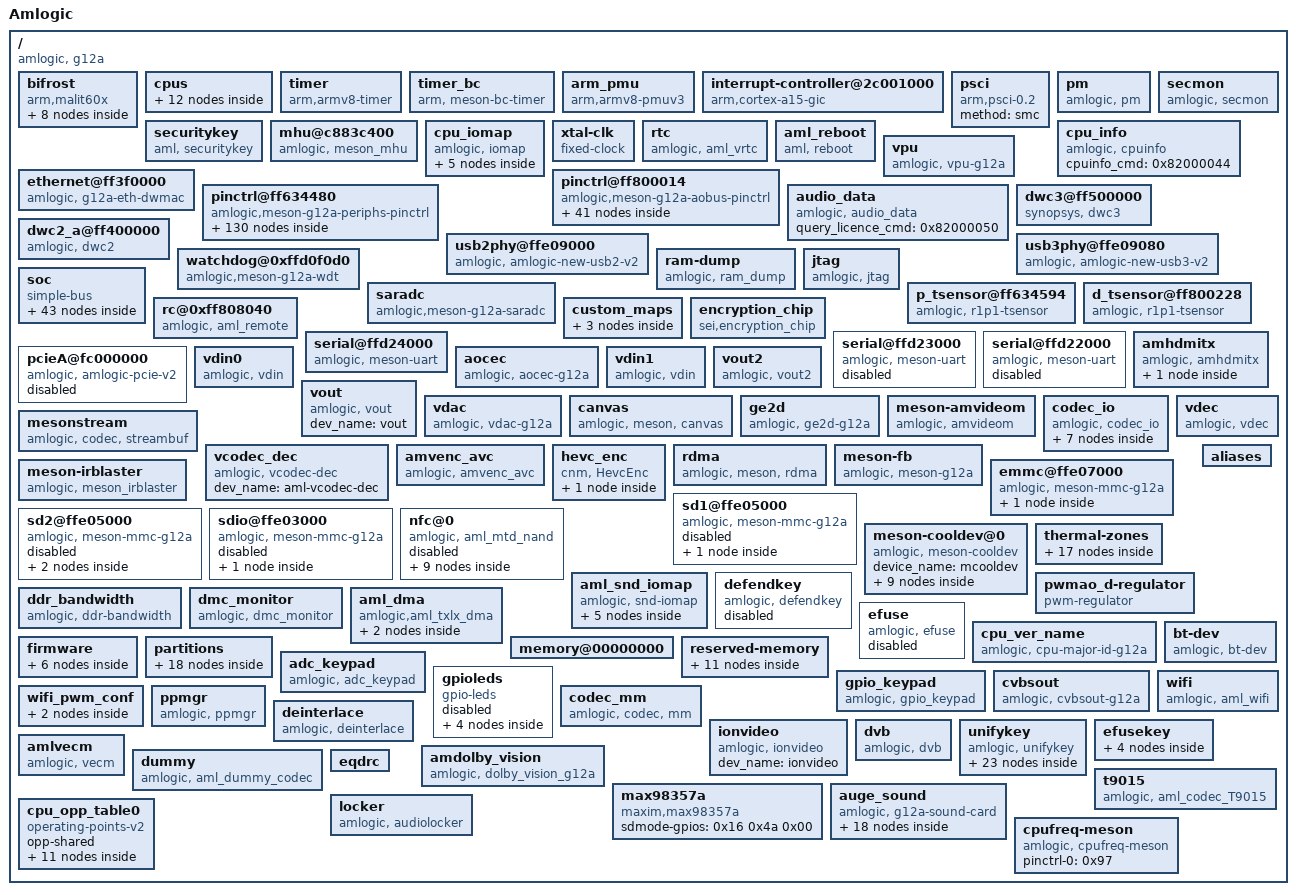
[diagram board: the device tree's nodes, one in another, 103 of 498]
/dts-v1/;

/ {
	model = "Amlogic";
	amlogic-dt-id = "g12a_SEI501";
	compatible = "amlogic, g12a";
	interrupt-parent = <0x01>;
	#address-cells = <0x02>;
	#size-cells = <0x02>;

	bifrost {
		compatible = "arm,malit60x\0arm,malit6xx\0arm,mali-midgard";
		#cooling-cells = <0x02>;
		reg = <0x00 0xffe40000 0x00 0x4000 0x00 0xffd01000 0x00 0x1000 0x00 0xff800000 0x00 0x1000 0x00 0xff63c000 0x00 0x1000 0x00 0xffd01000 0x00 0x1000>;
		interrupt-parent = <0x01>;
		interrupts = <0x00 0xa0 0x04 0x00 0xa1 0x04 0x00 0xa2 0x04>;
		interrupt-names = "GPU\0MMU\0JOB";
		num_of_pp = <0x02>;
		sc_mpp = <0x01>;
		clocks = <0x02 0x83 0x02 0x07>;
		clock-names = "gpu_mux\0gp0_pll";
		tbl = <0x03 0x04 0x05 0x06 0x07 0x07>;
		linux,phandle = <0x98>;
		phandle = <0x98>;

		clk125_cfg {
			clk_freq = <0x7735940>;
			clk_parent = "fclk_div4";
			clkp_freq = <0x1dcd6500>;
			clk_reg = <0xa03>;
			voltage = <0x47e>;
			keep_count = <0x05>;
			threshold = <0x1e 0x78>;
			linux,phandle = <0x99>;
			phandle = <0x99>;
		};

		dvfs250_cfg {
			clk_freq = <0xee6b280>;
			clk_parent = "fclk_div4";
			clkp_freq = <0x1dcd6500>;
			clk_reg = <0xa01>;
			voltage = <0x47e>;
			keep_count = <0x05>;
			threshold = <0x50 0xaa>;
			linux,phandle = <0x9a>;
			phandle = <0x9a>;
		};

		dvfs285_cfg {
			clk_freq = <0x1107a76d>;
			clk_parent = "fclk_div7";
			clkp_freq = <0x1107a76d>;
			clk_reg = <0xe00>;
			voltage = <0x47e>;
			keep_count = <0x05>;
			threshold = <0x64 0xbe>;
			linux,phandle = <0x03>;
			phandle = <0x03>;
		};

		dvfs400_cfg {
			clk_freq = <0x17d78400>;
			clk_parent = "fclk_div5";
			clkp_freq = <0x17d78400>;
			clk_reg = <0xc00>;
			voltage = <0x47e>;
			keep_count = <0x05>;
			threshold = <0x98 0xcf>;
			linux,phandle = <0x04>;
			phandle = <0x04>;
		};

		dvfs500_cfg {
			clk_freq = <0x1dcd6500>;
			clk_parent = "fclk_div4";
			clkp_freq = <0x1dcd6500>;
			clk_reg = <0xa00>;
			voltage = <0x47e>;
			keep_count = <0x05>;
			threshold = <0xb4 0xdc>;
			linux,phandle = <0x05>;
			phandle = <0x05>;
		};

		dvfs666_cfg {
			clk_freq = <0x27bc86aa>;
			clk_parent = "fclk_div3";
			clkp_freq = <0x27bc86aa>;
			clk_reg = <0x800>;
			voltage = <0x47e>;
			keep_count = <0x05>;
			threshold = <0xd2 0xec>;
			linux,phandle = <0x06>;
			phandle = <0x06>;
		};

		dvfs800_cfg {
			clk_freq = <0x2faf0800>;
			clk_parent = "fclk_div2p5";
			clkp_freq = <0x2faf0800>;
			clk_reg = <0x600>;
			voltage = <0x47e>;
			keep_count = <0x05>;
			threshold = <0xe6 0xff>;
			linux,phandle = <0x9b>;
			phandle = <0x9b>;
		};

		dvfs850_cfg {
			clk_freq = <0x326cef80>;
			clk_parent = "gp0_pll";
			clkp_freq = <0x326cef80>;
			clk_reg = <0x200>;
			voltage = <0x47e>;
			keep_count = <0x05>;
			threshold = <0xe6 0xff>;
			linux,phandle = <0x07>;
			phandle = <0x07>;
		};
	};

	cpus {
		#address-cells = <0x02>;
		#size-cells = <0x00>;
		linux,phandle = <0x9c>;
		phandle = <0x9c>;

		cpu-map {

			cluster0 {
				linux,phandle = <0x9d>;
				phandle = <0x9d>;

				core0 {
					cpu = <0x08>;
				};

				core1 {
					cpu = <0x09>;
				};

				core2 {
					cpu = <0x0a>;
				};

				core3 {
					cpu = <0x0b>;
				};
			};
		};

		cpu@0 {
			device_type = "cpu";
			compatible = "arm,cortex-a53\0arm,armv8";
			reg = <0x00 0x00>;
			enable-method = "psci";
			cpu-idle-states = <0x0c>;
			clocks = <0x02 0x17 0x02 0x16 0x02 0x00>;
			clock-names = "core_clk\0low_freq_clk_parent\0high_freq_clk_parent";
			operating-points-v2 = <0x0d>;
			cpu-supply = <0x0e>;
			voltage-tolerance = <0x00>;
			clock-latency = <0xc350>;
			linux,phandle = <0x08>;
			phandle = <0x08>;
		};

		cpu@1 {
			device_type = "cpu";
			compatible = "arm,cortex-a53\0arm,armv8";
			reg = <0x00 0x01>;
			enable-method = "psci";
			cpu-idle-states = <0x0c>;
			clocks = <0x02 0x17 0x02 0x16 0x02 0x00>;
			clock-names = "core_clk\0low_freq_clk_parent\0high_freq_clk_parent";
			operating-points-v2 = <0x0d>;
			cpu-supply = <0x0e>;
			voltage-tolerance = <0x00>;
			clock-latency = <0xc350>;
			linux,phandle = <0x09>;
			phandle = <0x09>;
		};

		cpu@2 {
			device_type = "cpu";
			compatible = "arm,cortex-a53\0arm,armv8";
			reg = <0x00 0x02>;
			enable-method = "psci";
			cpu-idle-states = <0x0c>;
			clocks = <0x02 0x17 0x02 0x16 0x02 0x00>;
			clock-names = "core_clk\0low_freq_clk_parent\0high_freq_clk_parent";
			operating-points-v2 = <0x0d>;
			cpu-supply = <0x0e>;
			voltage-tolerance = <0x00>;
			clock-latency = <0xc350>;
			linux,phandle = <0x0a>;
			phandle = <0x0a>;
		};

		cpu@3 {
			device_type = "cpu";
			compatible = "arm,cortex-a53\0arm,armv8";
			reg = <0x00 0x03>;
			enable-method = "psci";
			cpu-idle-states = <0x0c>;
			clocks = <0x02 0x17 0x02 0x16 0x02 0x00>;
			clock-names = "core_clk\0low_freq_clk_parent\0high_freq_clk_parent";
			operating-points-v2 = <0x0d>;
			cpu-supply = <0x0e>;
			voltage-tolerance = <0x00>;
			clock-latency = <0xc350>;
			linux,phandle = <0x0b>;
			phandle = <0x0b>;
		};

		idle-states {
			entry-method = "arm,psci-0.2";

			cpu-sleep-0 {
				compatible = "arm,idle-state";
				arm,psci-suspend-param = <0x10000>;
				local-timer-stop;
				entry-latency-us = <0x1388>;
				exit-latency-us = <0x1388>;
				min-residency-us = <0x3a98>;
				linux,phandle = <0x0c>;
				phandle = <0x0c>;
			};
		};
	};

	timer {
		compatible = "arm,armv8-timer";
		interrupts = <0x01 0x0d 0xff08 0x01 0x0e 0xff08 0x01 0x0b 0xff08 0x01 0x0a 0xff08>;
	};

	timer_bc {
		compatible = "arm, meson-bc-timer";
		reg = <0x00 0xffd0f190 0x00 0x04 0x00 0xffd0f194 0x00 0x04>;
		timer_name = "Meson TimerF";
		clockevent-rating = <0x12c>;
		clockevent-shift = <0x14>;
		clockevent-features = <0x23>;
		interrupts = <0x00 0x3c 0x01>;
		bit_enable = <0x10>;
		bit_mode = <0x0c>;
		bit_resolution = <0x00>;
	};

	arm_pmu {
		compatible = "arm,armv8-pmuv3";
		interrupts = <0x00 0x89 0x04>;
		reg = <0x00 0xff634400 0x00 0x1000>;
		sys_cpu_status0_offset = <0xa0>;
		sys_cpu_status0_pmuirq_mask = <0x0f>;
		relax_timer_ns = <0x989680>;
		max_wait_cnt = <0x2710>;
	};

	interrupt-controller@2c001000 {
		compatible = "arm,cortex-a15-gic\0arm,cortex-a9-gic";
		#interrupt-cells = <0x03>;
		#address-cells = <0x00>;
		interrupt-controller;
		reg = <0x00 0xffc01000 0x00 0x1000 0x00 0xffc02000 0x00 0x100>;
		interrupts = <0x01 0x09 0xf04>;
		linux,phandle = <0x01>;
		phandle = <0x01>;
	};

	psci {
		compatible = "arm,psci-0.2";
		method = "smc";
	};

	pm {
		compatible = "amlogic, pm";
		status = "okay";
		device_name = "aml_pm";
		reg = <0x00 0xff8000a8 0x00 0x04 0x00 0xff80023c 0x00 0x04>;
		linux,phandle = <0x9e>;
		phandle = <0x9e>;
	};

	secmon {
		compatible = "amlogic, secmon";
		memory-region = <0x0f>;
		in_base_func = <0x82000020>;
		out_base_func = <0x82000021>;
		reserve_mem_size = <0x300000>;
	};

	securitykey {
		compatible = "aml, securitykey";
		storage_query = <0x82000060>;
		storage_read = <0x82000061>;
		storage_write = <0x82000062>;
		storage_tell = <0x82000063>;
		storage_verify = <0x82000064>;
		storage_status = <0x82000065>;
		storage_list = <0x82000067>;
		storage_remove = <0x82000068>;
		storage_in_func = <0x82000023>;
		storage_out_func = <0x82000024>;
		storage_block_func = <0x82000025>;
		storage_size_func = <0x82000027>;
		storage_set_enctype = <0x8200006a>;
		storage_get_enctype = <0x8200006b>;
		storage_version = <0x8200006c>;
	};

	mhu@c883c400 {
		compatible = "amlogic, meson_mhu";
		reg = <0x00 0xff63c400 0x00 0x4c 0x00 0xfffe7000 0x00 0x800>;
		interrupts = <0x00 0xd1 0x01 0x00 0xd2 0x01>;
		#mbox-cells = <0x01>;
		mbox-names = "cpu_to_scp_low\0cpu_to_scp_high";
		mboxes = <0x10 0x00 0x10 0x01>;
		linux,phandle = <0x10>;
		phandle = <0x10>;
	};

	cpu_iomap {
		compatible = "amlogic, iomap";
		#address-cells = <0x02>;
		#size-cells = <0x02>;
		ranges;

		io_cbus_base {
			reg = <0x00 0xffd00000 0x00 0x26000>;
		};

		io_apb_base {
			reg = <0x00 0xffe01000 0x00 0x7f000>;
		};

		io_aobus_base {
			reg = <0x00 0xff800000 0x00 0xb000>;
		};

		io_vapb_base {
			reg = <0x00 0xff900000 0x00 0x50000>;
		};

		io_hiu_base {
			reg = <0x00 0xff63c000 0x00 0x2000>;
		};
	};

	xtal-clk {
		compatible = "fixed-clock";
		clock-frequency = <0x16e3600>;
		clock-output-names = "xtal";
		#clock-cells = <0x00>;
		linux,phandle = <0x14>;
		phandle = <0x14>;
	};

	rtc {
		compatible = "amlogic, aml_vrtc";
		alarm_reg_addr = <0xff8000a8>;
		timer_e_addr = <0xffd0f188>;
		init_date = "2015/01/01";
		status = "okay";
	};

	cpu_info {
		compatible = "amlogic, cpuinfo";
		status = "okay";
		cpuinfo_cmd = <0x82000044>;
	};

	aml_reboot {
		compatible = "aml, reboot";
		sys_reset = <0x84000009>;
		sys_poweroff = <0x84000008>;
	};

	vpu {
		compatible = "amlogic, vpu-g12a";
		dev_name = "vpu";
		status = "okay";
		clocks = <0x02 0x95 0x02 0x4c 0x02 0x87 0x02 0x8b 0x02 0x8c>;
		clock-names = "vapb_clk\0vpu_intr_gate\0vpu_clk0\0vpu_clk1\0vpu_clk";
		clk_level = <0x07>;
	};

	ethernet@ff3f0000 {
		compatible = "amlogic, g12a-eth-dwmac\0snps,dwmac";
		reg = <0x00 0xff3f0000 0x00 0x10000 0x00 0xff634540 0x00 0x08 0x00 0xff64c000 0x00 0xa0>;
		reg-names = "eth_base\0eth_cfg\0eth_pll";
		interrupts = <0x00 0x08 0x01>;
		interrupt-names = "macirq";
		status = "okay";
		clocks = <0x02 0x38>;
		clock-names = "ethclk81";
		pll_val = <0x9c0040a 0x927e0000 0xac5f49e5>;
		analog_val = <0x20200000 0xc000 0x23>;
		pinctrl-names = "internal_eth_pins";
		pinctrl-0 = <0x11>;
		mc_val = <0x4be04>;
		internal_phy = <0x01>;
		linux,phandle = <0x9f>;
		phandle = <0x9f>;
	};

	pinctrl@ff800014 {
		compatible = "amlogic,meson-g12a-aobus-pinctrl";
		#address-cells = <0x02>;
		#size-cells = <0x02>;
		ranges;
		linux,phandle = <0xa0>;
		phandle = <0xa0>;

		ao-bank@ff800014 {
			reg = <0x00 0xff800014 0x00 0x08 0x00 0xff800024 0x00 0x14 0x00 0xff80001c 0x00 0x08>;
			reg-names = "mux\0gpio\0drive-strength";
			gpio-controller;
			#gpio-cells = <0x02>;
			linux,phandle = <0x15>;
			phandle = <0x15>;
		};

		sd_to_ao_uart_clr_pins {
			linux,phandle = <0x3e>;
			phandle = <0x3e>;

			mux {
				groups = "GPIOAO_0\0GPIOAO_1";
				function = "gpio_aobus";
			};
		};

		sd_to_ao_uart_pins {
			linux,phandle = <0x40>;
			phandle = <0x40>;

			mux {
				groups = "uart_ao_tx_a\0uart_ao_rx_a";
				function = "uart_ao_a";
				bias-pull-up;
				input-enable;
			};
		};

		ao_uart {
			linux,phandle = <0xa1>;
			phandle = <0xa1>;

			mux {
				groups = "uart_ao_tx_a\0uart_ao_rx_a";
				function = "uart_ao_a";
			};
		};

		ao_b_uart {
			linux,phandle = <0x1a>;
			phandle = <0x1a>;

			mux {
				groups = "uart_ao_tx_b_2\0uart_ao_rx_b_3";
				function = "uart_ao_b";
			};
		};

		ao_i2c_pins1 {
			linux,phandle = <0xa2>;
			phandle = <0xa2>;

			mux {
				groups = "i2c_ao_sck\0i2c_ao_sda";
				function = "i2c_ao";
				drive-strength = <0x02>;
			};
		};

		ao_i2c_pins2 {
			linux,phandle = <0xa3>;
			phandle = <0xa3>;

			mux {
				groups = "i2c_ao_sck_e\0i2c_ao_sda_e";
				function = "i2c_ao";
				drive-strength = <0x02>;
			};
		};

		ao_i2c_slave_pins {
			linux,phandle = <0x19>;
			phandle = <0x19>;

			mux {
				groups = "i2c_ao_slave_sck\0i2c_ao_slave_sda";
				function = "i2c_ao_slave";
			};
		};

		pwm_ao_a {
			linux,phandle = <0xa4>;
			phandle = <0xa4>;

			mux {
				groups = "pwm_ao_a";
				function = "pwm_ao_a";
			};
		};

		pwm_ao_a_hiz {
			linux,phandle = <0xa5>;
			phandle = <0xa5>;

			mux {
				groups = "pwm_ao_a_hiz";
				function = "pwm_ao_a";
			};
		};

		pwm_ao_b {
			linux,phandle = <0xa6>;
			phandle = <0xa6>;

			mux {
				groups = "pwm_ao_b";
				function = "pwm_ao_b";
			};
		};

		pwm_ao_c_pins1 {
			linux,phandle = <0xa7>;
			phandle = <0xa7>;

			mux {
				groups = "pwm_ao_c_4";
				function = "pwm_ao_c";
			};
		};

		pwm_ao_c_pins2 {
			linux,phandle = <0xa8>;
			phandle = <0xa8>;

			mux {
				groups = "pwm_ao_c_6";
				function = "pwm_ao_c";
			};
		};

		pwm_ao_c_hiz {
			linux,phandle = <0xa9>;
			phandle = <0xa9>;

			mux {
				groups = "pwm_ao_c_hiz_4";
				function = "pwm_ao_c";
			};
		};

		pwm_ao_d_pins1 {
			linux,phandle = <0xaa>;
			phandle = <0xaa>;

			mux {
				groups = "pwm_ao_d_5";
				function = "pwm_ao_d";
			};
		};

		pwm_ao_d_pins2 {
			linux,phandle = <0xab>;
			phandle = <0xab>;

			mux {
				groups = "pwm_ao_d_10";
				function = "pwm_ao_d";
			};
		};

		pwm_ao_d_pins3 {
			linux,phandle = <0x97>;
			phandle = <0x97>;

			mux {
				groups = "pwm_ao_d_e";
				function = "pwm_ao_d";
			};
		};

		ao_ceca {
			linux,phandle = <0xac>;
			phandle = <0xac>;

			mux {
				groups = "cec_ao_a";
				function = "cec_ao";
			};
		};

		ao_cecb {
			linux,phandle = <0xad>;
			phandle = <0xad>;

			mux {
				groups = "cec_ao_b";
				function = "cec_ao";
			};
		};

		remote_pin {
			linux,phandle = <0x25>;
			phandle = <0x25>;

			mux {
				groups = "remote_input_ao";
				function = "remote_input_ao";
			};
		};

		irblaster_pin {
			linux,phandle = <0x37>;
			phandle = <0x37>;

			mux {
				groups = "remote_out_ao";
				function = "remote_out_ao";
			};
		};
	};

	pinctrl@ff634480 {
		compatible = "amlogic,meson-g12a-periphs-pinctrl";
		#address-cells = <0x02>;
		#size-cells = <0x02>;
		ranges;
		linux,phandle = <0xae>;
		phandle = <0xae>;

		banks@ff6346c0 {
			reg = <0x00 0xff6346c0 0x00 0x40 0x00 0xff6344e8 0x00 0x18 0x00 0xff634520 0x00 0x18 0x00 0xff634440 0x00 0x4c 0x00 0xff634740 0x00 0x1c>;
			reg-names = "mux\0pull\0pull-enable\0gpio\0drive-strength";
			gpio-controller;
			#gpio-cells = <0x02>;
			linux,phandle = <0x16>;
			phandle = <0x16>;
		};

		emmc_clk_cmd_pins {
			linux,phandle = <0x38>;
			phandle = <0x38>;

			mux {
				groups = "emmc_clk\0emmc_cmd";
				function = "emmc";
				input-enable;
				bias-pull-up;
			};
		};

		emmc_conf_pull_up {
			linux,phandle = <0x39>;
			phandle = <0x39>;

			mux {
				groups = "emmc_nand_d7\0emmc_nand_d6\0emmc_nand_d5\0emmc_nand_d4\0emmc_nand_d3\0emmc_nand_d2\0emmc_nand_d1\0emmc_nand_d0\0emmc_clk\0emmc_cmd";
				function = "emmc";
				input-enable;
				bias-pull-up;
			};
		};

		emmc_conf_pull_done {
			linux,phandle = <0x3a>;
			phandle = <0x3a>;

			mux {
				groups = "emmc_nand_ds";
				function = "emmc";
				input-enable;
				bias-pull-down;
			};
		};

		sd_clk_cmd_pins {
			linux,phandle = <0x3c>;
			phandle = <0x3c>;

			mux {
				groups = "sdcard_cmd_c";
				function = "sdcard";
				input-enable;
				bias-pull-up;
				drive-strength = <0x03>;
			};

			mux1 {
				groups = "sdcard_clk_c";
				function = "sdcard";
				bias-pull-up;
				output-high;
				drive-strength = <0x03>;
			};
		};

		sd_all_pins {
			linux,phandle = <0x3b>;
			phandle = <0x3b>;

			mux {
				groups = "sdcard_d0_c\0sdcard_d1_c\0sdcard_d2_c\0sdcard_d3_c\0sdcard_cmd_c";
				function = "sdcard";
				input-enable;
				bias-pull-up;
				drive-strength = <0x03>;
			};

			mux1 {
				groups = "sdcard_clk_c";
				function = "sdcard";
				bias-pull-up;
				output-high;
				drive-strength = <0x03>;
			};
		};

		sd_1bit_pins {
			linux,phandle = <0x3d>;
			phandle = <0x3d>;

			mux {
				groups = "sdcard_d0_c\0sdcard_cmd_c";
				function = "sdcard";
				input-enable;
				bias-pull-up;
				drive-strength = <0x03>;
			};

			mux1 {
				groups = "sdcard_clk_c";
				function = "sdcard";
				bias-pull-up;
				output-high;
				drive-strength = <0x03>;
			};
		};

		sd_clr_all_pins {
			linux,phandle = <0x44>;
			phandle = <0x44>;

			mux {
				groups = "GPIOC_0\0GPIOC_1\0GPIOC_2\0GPIOC_3\0GPIOC_5";
				function = "gpio_periphs";
				output-high;
			};

			mux1 {
				groups = "GPIOC_4";
				function = "gpio_periphs";
				output-low;
			};
		};

		sd_clr_noall_pins {
			linux,phandle = <0x43>;
			phandle = <0x43>;

			mux {
				groups = "GPIOC_0\0GPIOC_1\0GPIOC_4\0GPIOC_5";
				function = "gpio_periphs";
				output-high;
			};
		};

		ao_to_sd_uart_pins {
			linux,phandle = <0x3f>;
			phandle = <0x3f>;

			mux {
				groups = "uart_ao_tx_a_c3\0uart_ao_rx_a_c2";
				function = "uart_ao_a_ee";
				bias-pull-up;
				input-enable;
			};
		};

		sdio_clk_cmd_pins {
			linux,phandle = <0x48>;
			phandle = <0x48>;

			mux {
				groups = "sdio_clk\0sdio_cmd";
				function = "sdio";
				input-enable;
				bias-pull-up;
				drive-strength = <0x03>;
			};
		};

		sdio_all_pins {
			linux,phandle = <0x47>;
			phandle = <0x47>;

			mux {
				groups = "sdio_d0\0sdio_d1\0sdio_d2\0sdio_d3\0sdio_clk\0sdio_cmd";
				function = "sdio";
				input-enable;
				bias-pull-up;
				drive-strength = <0x03>;
			};
		};

		sdio_x_clk_cmd_pins {
			linux,phandle = <0x46>;
			phandle = <0x46>;

			mux {
				groups = "GPIOX_5";
				function = "gpio_periphs";
				input-enable;
				bias-pull-up;
				drive-strength = <0x03>;
			};

			mux1 {
				groups = "GPIOX_4";
				function = "gpio_periphs";
				bias-pull-up;
				output-high;
				drive-strength = <0x03>;
			};
		};

		sdio_x_all_pins {
			linux,phandle = <0x45>;
			phandle = <0x45>;

			mux {
				groups = "GPIOX_0\0GPIOX_1\0GPIOX_2\0GPIOX_3\0GPIOX_5";
				function = "gpio_periphs";
				input-enable;
				bias-pull-up;
				drive-strength = <0x03>;
			};

			mux1 {
				groups = "GPIOX_4";
				function = "gpio_periphs";
				bias-pull-up;
				output-high;
				drive-strength = <0x03>;
			};
		};

		sdio_x_en_pins {
			linux,phandle = <0x42>;
			phandle = <0x42>;

			mux {
				groups = "sdio_dummy";
				function = "sdio";
				bias-pull-up;
				output-high;
			};
		};

		sdio_x_clr_pins {
			linux,phandle = <0x41>;
			phandle = <0x41>;

			mux {
				groups = "GPIOV_0";
				function = "gpio_periphs";
				bias-pull-up;
				output-low;
			};

			mux1 {
				groups = "GPIOX_4";
				function = "gpio_periphs";
				output-low;
			};
		};

		all_nand_pins {
			linux,phandle = <0x49>;
			phandle = <0x49>;

			mux {
				groups = "emmc_nand_d0\0emmc_nand_d1\0emmc_nand_d2\0emmc_nand_d3\0emmc_nand_d4\0emmc_nand_d5\0emmc_nand_d6\0emmc_nand_d7\0nand_ce0\0nand_ale\0nand_cle\0nand_wen_clk\0nand_ren_wr\0nand_rb0";
				function = "nand";
				input-enable;
			};
		};

		nand_cs {
			linux,phandle = <0x4a>;
			phandle = <0x4a>;

			mux {
				groups = "nand_ce0";
				function = "nand";
			};
		};

		i2c0_pins1 {
			linux,phandle = <0xaf>;
			phandle = <0xaf>;

			mux {
				groups = "i2c0_sda_c\0i2c0_sck_c";
				function = "i2c0";
				drive-strength = <0x02>;
			};
		};

		i2c0_pins2 {
			linux,phandle = <0x17>;
			phandle = <0x17>;

			mux {
				groups = "i2c0_sda_z0\0i2c0_sck_z1";
				function = "i2c0";
				drive-strength = <0x02>;
			};
		};

		i2c0_pins3 {
			linux,phandle = <0xb0>;
			phandle = <0xb0>;

			mux {
				groups = "i2c0_sda_z7\0i2c0_sck_z8";
				function = "i2c0";
				drive-strength = <0x02>;
			};
		};

		i2c1_pins1 {
			linux,phandle = <0xb1>;
			phandle = <0xb1>;

			mux {
				groups = "i2c1_sda_x\0i2c1_sck_x";
				function = "i2c1";
				drive-strength = <0x02>;
			};
		};

		i2c1_pins2 {
			linux,phandle = <0xb2>;
			phandle = <0xb2>;

			mux {
				groups = "i2c1_sda_h2\0i2c1_sck_h3";
				function = "i2c1";
				drive-strength = <0x02>;
			};
		};

		i2c1_pins3 {
			linux,phandle = <0xb3>;
			phandle = <0xb3>;

			mux {
				groups = "i2c1_sda_h6\0i2c1_sck_h7";
				function = "i2c1";
				drive-strength = <0x02>;
			};
		};

		i2c2_pins1 {
			linux,phandle = <0xb4>;
			phandle = <0xb4>;

			mux {
				groups = "i2c2_sda_x\0i2c2_sck_x";
				function = "i2c2";
				drive-strength = <0x02>;
			};
		};

		i2c2_pins2 {
			linux,phandle = <0xb5>;
			phandle = <0xb5>;

			mux {
				groups = "i2c2_sda_z\0i2c2_sck_z";
				function = "i2c2";
				drive-strength = <0x02>;
			};
		};

		i2c3_pins1 {
			linux,phandle = <0x31>;
			phandle = <0x31>;

			mux {
				groups = "i2c3_sda_h\0i2c3_sck_h";
				function = "i2c3";
				drive-strength = <0x02>;
			};
		};

		i2c3_pins2 {
			linux,phandle = <0x18>;
			phandle = <0x18>;

			mux {
				groups = "i2c3_sda_a\0i2c3_sck_a";
				function = "i2c3";
				drive-strength = <0x02>;
			};
		};

		pwm_a {
			linux,phandle = <0xb6>;
			phandle = <0xb6>;

			mux {
				groups = "pwm_a";
				function = "pwm_a";
			};
		};

		pwm_b_pins1 {
			linux,phandle = <0xb7>;
			phandle = <0xb7>;

			mux {
				groups = "pwm_b_x7";
				function = "pwm_b";
			};
		};

		pwm_b_pins2 {
			linux,phandle = <0xb8>;
			phandle = <0xb8>;

			mux {
				groups = "pwm_b_x19";
				function = "pwm_b";
			};
		};

		pwm_c_pins1 {
			linux,phandle = <0xb9>;
			phandle = <0xb9>;

			mux {
				groups = "pwm_c_c4";
				function = "pwm_c";
			};
		};

		pwm_c_pins2 {
			linux,phandle = <0xba>;
			phandle = <0xba>;

			mux {
				groups = "pwm_c_x5";
				function = "pwm_c";
			};
		};

		pwm_c_pins3 {
			linux,phandle = <0xbb>;
			phandle = <0xbb>;

			mux {
				groups = "pwm_c_x8";
				function = "pwm_c";
			};
		};

		pwm_d_pins1 {
			linux,phandle = <0xbc>;
			phandle = <0xbc>;

			mux {
				groups = "pwm_d_x3";
				function = "pwm_d";
			};
		};

		pwm_d_pins2 {
			linux,phandle = <0xbd>;
			phandle = <0xbd>;

			mux {
				groups = "pwm_d_x6";
				function = "pwm_d";
			};
		};

		pwm_e {
			linux,phandle = <0x6a>;
			phandle = <0x6a>;

			mux {
				groups = "pwm_e";
				function = "pwm_e";
			};
		};

		pwm_f_pins1 {
			linux,phandle = <0xbe>;
			phandle = <0xbe>;

			mux {
				groups = "pwm_f_x";
				function = "pwm_f";
			};
		};

		pwm_f_pins2 {
			linux,phandle = <0xbf>;
			phandle = <0xbf>;

			mux {
				groups = "pwm_f_h";
				function = "pwm_f";
			};
		};

		spicc0_pins_x {
			linux,phandle = <0xc0>;
			phandle = <0xc0>;

			mux {
				groups = "spi0_mosi_x\0spi0_miso_x\0spi0_clk_x";
				function = "spi0";
				drive-strength = <0x01>;
			};
		};

		spicc0_pins_c {
			linux,phandle = <0xc1>;
			phandle = <0xc1>;

			mux {
				groups = "spi0_mosi_c\0spi0_miso_c\0spi0_ss0_c\0spi0_clk_c";
				function = "spi0";
				drive-strength = <0x01>;
			};
		};

		spicc1_pins {
			linux,phandle = <0xc2>;
			phandle = <0xc2>;

			mux {
				groups = "spi1_mosi\0spi1_miso\0spi1_clk";
				function = "spi1";
				drive-strength = <0x01>;
			};
		};

		a_uart {
			linux,phandle = <0x2a>;
			phandle = <0x2a>;

			mux {
				groups = "uart_tx_a\0uart_rx_a\0uart_cts_a\0uart_rts_a";
				function = "uart_a";
			};
		};

		b_uart {
			linux,phandle = <0x2b>;
			phandle = <0x2b>;

			mux {
				groups = "uart_tx_b\0uart_rx_b";
				function = "uart_b";
			};
		};

		c_uart {
			linux,phandle = <0x2c>;
			phandle = <0x2c>;

			mux {
				groups = "uart_tx_c\0uart_rx_c";
				function = "uart_c";
			};
		};

		hdmitx_hpd {
			linux,phandle = <0x2e>;
			phandle = <0x2e>;

			mux {
				groups = "hdmitx_hpd_in";
				function = "hdmitx";
				bias-disable;
			};
		};

		hdmitx_hpd_gpio {
			linux,phandle = <0x30>;
			phandle = <0x30>;

			mux {
				groups = "GPIOH_1";
				function = "gpio_periphs";
				bias-disable;
			};
		};

		hdmitx_ddc {
			linux,phandle = <0x2f>;
			phandle = <0x2f>;

			mux {
				groups = "hdmitx_sda\0hdmitx_sck";
				function = "hdmitx";
				bias-disable;
				drive-strength = <0x03>;
			};
		};

		ee_ceca {
			linux,phandle = <0x32>;
			phandle = <0x32>;

			mux {
				groups = "cec_ao_a_ee";
				function = "cec_ao_ee";
			};
		};

		ee_cecb {
			linux,phandle = <0x33>;
			phandle = <0x33>;

			mux {
				groups = "cec_ao_b_ee";
				function = "cec_ao_ee";
			};
		};

		internal_eth_pins {
			linux,phandle = <0x11>;
			phandle = <0x11>;

			mux {
				groups = "eth_link_led\0eth_act_led";
				function = "eth";
			};
		};

		internal_gpio_pins {
			linux,phandle = <0xc3>;
			phandle = <0xc3>;

			mux {
				groups = "GPIOZ_14\0GPIOZ_15";
				function = "gpio_periphs";
				bias-disable;
				input-enable;
			};
		};

		external_eth_pins {
			linux,phandle = <0xc4>;
			phandle = <0xc4>;

			mux {
				groups = "eth_mdio\0eth_mdc\0eth_rgmii_rx_clk\0eth_rx_dv\0eth_rxd0\0eth_rxd1\0eth_rxd2_rgmii\0eth_rxd3_rgmii\0eth_rgmii_tx_clk\0eth_txen\0eth_txd0\0eth_txd1\0eth_txd2_rgmii\0eth_txd3_rgmii";
				function = "eth";
				drive-strength = <0x03>;
			};
		};

		tdmout_a {
			linux,phandle = <0x1d>;
			phandle = <0x1d>;

			mux {
				groups = "tdma_sclk\0tdma_fs\0tdma_dout0";
				function = "tdma_out";
			};
		};

		tdmb_mclk {
			linux,phandle = <0x1e>;
			phandle = <0x1e>;

			mux {
				groups = "mclk0_a";
				function = "mclk0";
				drive-strength = <0x02>;
			};
		};

		tdmout_b {
			linux,phandle = <0x1f>;
			phandle = <0x1f>;

			mux {
				groups = "tdmb_sclk\0tdmb_fs\0tdmb_dout0";
				function = "tdmb_out";
				drive-strength = <0x02>;
			};
		};

		tdmin_b {
			linux,phandle = <0x20>;
			phandle = <0x20>;

			mux {
				groups = "tdmb_din1";
				function = "tdmb_in";
				drive-strength = <0x02>;
			};
		};

		tdmc_mclk {
			linux,phandle = <0x21>;
			phandle = <0x21>;

			mux {
				groups = "mclk1_a";
				function = "mclk1";
			};
		};

		tdmin_c {
			linux,phandle = <0x22>;
			phandle = <0x22>;

			mux {
				groups = "tdmc_din1_a";
				function = "tdmc_in";
			};
		};

		spdifin {
			linux,phandle = <0xc5>;
			phandle = <0xc5>;

			mux {
				groups = "spdif_in_h";
				function = "spdif_in";
			};
		};

		spdifout {
			linux,phandle = <0x23>;
			phandle = <0x23>;

			mux {
				groups = "spdif_out_h";
				function = "spdif_out";
			};
		};

		pdmin {
			linux,phandle = <0x24>;
			phandle = <0x24>;

			mux {
				groups = "pdm_din0_z\0pdm_din1_z\0pdm_dclk_z";
				function = "pdm";
			};
		};
	};

	audio_data {
		compatible = "amlogic, audio_data";
		query_licence_cmd = <0x82000050>;
		status = "okay";
		linux,phandle = <0xc6>;
		phandle = <0xc6>;
	};

	dwc3@ff500000 {
		compatible = "synopsys, dwc3";
		status = "okay";
		reg = <0x00 0xff500000 0x00 0x100000>;
		interrupts = <0x00 0x1e 0x04>;
		usb-phy = <0x12 0x13>;
		cpu-type = "gxl";
		clock-src = "usb3.0";
		clocks = <0x02 0x41>;
		clock-names = "dwc_general";
		linux,phandle = <0xc7>;
		phandle = <0xc7>;
	};

	usb2phy@ffe09000 {
		compatible = "amlogic, amlogic-new-usb2-v2";
		status = "okay";
		reg = <0x00 0xffe09000 0x00 0x80 0x00 0xffd01008 0x00 0x100 0x00 0xff636000 0x00 0x2000 0x00 0xff63a000 0x00 0x2000>;
		pll-setting-1 = <0x9400414>;
		pll-setting-2 = <0x927e0000>;
		pll-setting-3 = <0xac5f49e5>;
		pll-setting-4 = <0xfe18>;
		pll-setting-5 = <0x8000fff>;
		pll-setting-6 = <0x78000>;
		pll-setting-7 = <0xe0004>;
		pll-setting-8 = <0xe000c>;
		portnum = <0x02>;
		linux,phandle = <0x12>;
		phandle = <0x12>;
	};

	usb3phy@ffe09080 {
		compatible = "amlogic, amlogic-new-usb3-v2";
		status = "okay";
		reg = <0x00 0xffe09080 0x00 0x20>;
		phy-reg = <0xff646000>;
		phy-reg-size = <0x2000>;
		usb2-phy-reg = <0xffe09000>;
		usb2-phy-reg-size = <0x80>;
		interrupts = <0x00 0x10 0x04>;
		clocks = <0x02 0x18>;
		clock-names = "pcie_refpll";
		portnum = <0x01>;
		otg = <0x00>;
		linux,phandle = <0x13>;
		phandle = <0x13>;
	};

	dwc2_a@ff400000 {
		compatible = "amlogic, dwc2";
		status = "okay";
		device_name = "dwc2_a";
		reg = <0x00 0xff400000 0x00 0x40000>;
		interrupts = <0x00 0x1f 0x04>;
		pl-periph-id = <0x00>;
		clock-src = "usb0";
		port-id = <0x00>;
		port-type = <0x02>;
		port-speed = <0x00>;
		port-config = <0x00>;
		port-dma = <0x00>;
		port-id-mode = <0x00>;
		usb-fifo = <0x2d8>;
		cpu-type = "v2";
		phy-reg = <0xffe09000>;
		phy-reg-size = <0xa0>;
		phy-interface = <0x00>;
		clocks = <0x02 0x41 0x02 0x49>;
		clock-names = "usb_general\0usb1";
		controller-type = <0x01>;
		linux,phandle = <0xc8>;
		phandle = <0xc8>;
	};

	watchdog@0xffd0f0d0 {
		compatible = "amlogic,meson-g12a-wdt";
		status = "okay";
		reg = <0x00 0xffd0f0d0 0x00 0x10>;
		clock-names = "xtal";
		clocks = <0x14>;
		linux,phandle = <0xc9>;
		phandle = <0xc9>;
	};

	ram-dump {
		compatible = "amlogic, ram_dump";
		status = "okay";
	};

	jtag {
		compatible = "amlogic, jtag";
		status = "okay";
		select = "apao";
		jtagao-gpios = <0x15 0x06 0x00 0x15 0x07 0x00 0x15 0x08 0x00 0x15 0x09 0x00>;
		jtagee-gpios = <0x16 0x2a 0x00 0x16 0x2b 0x00 0x16 0x2e 0x00 0x16 0x2f 0x00>;
	};

	saradc {
		compatible = "amlogic,meson-g12a-saradc";
		status = "okay";
		#io-channel-cells = <0x01>;
		clocks = <0x14 0x02 0xeb>;
		clock-names = "xtal\0saradc_clk";
		interrupts = <0x00 0xc8 0x01>;
		reg = <0x00 0xff809000 0x00 0x48>;
		linux,phandle = <0x69>;
		phandle = <0x69>;
	};

	p_tsensor@ff634594 {
		compatible = "amlogic, r1p1-tsensor";
		device_name = "meson-pthermal";
		status = "okay";
		reg = <0x00 0xff634800 0x00 0x50 0x00 0xff800268 0x00 0x04>;
		cal_type = <0x01>;
		cal_a = <0x144>;
		cal_b = <0x1a8>;
		cal_c = <0xc57>;
		cal_d = <0x24c3>;
		rtemp = <0x1c138>;
		interrupts = <0x00 0x23 0x00>;
		clocks = <0x02 0xd2>;
		clock-names = "ts_comp";
		#thermal-sensor-cells = <0x01>;
		linux,phandle = <0x4e>;
		phandle = <0x4e>;
	};

	d_tsensor@ff800228 {
		compatible = "amlogic, r1p1-tsensor";
		device_name = "meson-dthermal";
		status = "okay";
		reg = <0x00 0xff634c00 0x00 0x50 0x00 0xff800230 0x00 0x04>;
		cal_type = <0x01>;
		cal_a = <0x144>;
		cal_b = <0x1a8>;
		cal_c = <0xc57>;
		cal_d = <0x24c3>;
		rtemp = <0x1c138>;
		interrupts = <0x00 0x24 0x00>;
		clocks = <0x02 0xd2>;
		clock-names = "ts_comp";
		#thermal-sensor-cells = <0x01>;
		linux,phandle = <0x54>;
		phandle = <0x54>;
	};

	soc {
		compatible = "simple-bus";
		#address-cells = <0x02>;
		#size-cells = <0x02>;
		ranges;

		cbus@ffd00000 {
			compatible = "simple-bus";
			reg = <0x00 0xffd00000 0x00 0x26000>;
			#address-cells = <0x02>;
			#size-cells = <0x02>;
			ranges = <0x00 0x00 0x00 0xffd00000 0x00 0x26000>;
			linux,phandle = <0xca>;
			phandle = <0xca>;

			interrupt-controller@f080 {
				compatible = "amlogic,meson-gpio-intc\0amlogic,meson-g12a-gpio-intc";
				reg = <0x00 0xf080 0x00 0x10>;
				interrupt-controller;
				#interrupt-cells = <0x02>;
				amlogic,channel-interrupts = <0x40 0x41 0x42 0x43 0x44 0x45 0x46 0x47>;
				status = "okay";
				linux,phandle = <0xcb>;
				phandle = <0xcb>;
			};

			meson_clk_msr {
				compatible = "amlogic, gxl_measure";
				reg = <0x00 0x18004 0x00 0x04 0x00 0x1800c 0x00 0x04>;
				ringctrl = <0xff6345fc>;
			};

			pwm@1b000 {
				compatible = "amlogic,g12a-ee-pwm";
				reg = <0x00 0x1b000 0x00 0x20>;
				#pwm-cells = <0x03>;
				clocks = <0x14 0x14 0x14 0x14>;
				clock-names = "clkin0\0clkin1\0clkin2\0clkin3";
				status = "disabled";
				linux,phandle = <0xcc>;
				phandle = <0xcc>;
			};

			pwm@1a000 {
				compatible = "amlogic,g12a-ee-pwm";
				reg = <0x00 0x1a000 0x00 0x20>;
				#pwm-cells = <0x03>;
				clocks = <0x14 0x14 0x14 0x14>;
				clock-names = "clkin0\0clkin1\0clkin2\0clkin3";
				status = "disabled";
				linux,phandle = <0xcd>;
				phandle = <0xcd>;
			};

			pwm@19000 {
				compatible = "amlogic,g12a-ee-pwm";
				reg = <0x00 0x19000 0x00 0x20>;
				#pwm-cells = <0x03>;
				clocks = <0x14 0x14 0x14 0x14>;
				clock-names = "clkin0\0clkin1\0clkin2\0clkin3";
				status = "okay";
				linux,phandle = <0x6c>;
				phandle = <0x6c>;
			};

			i2c@1f000 {
				compatible = "amlogic,meson-g12a-i2c";
				status = "okay";
				reg = <0x00 0x1f000 0x00 0x20>;
				interrupts = <0x00 0x15 0x01 0x00 0x5b 0x01>;
				#address-cells = <0x01>;
				#size-cells = <0x00>;
				clocks = <0x02 0x2a>;
				clock-names = "clk_i2c";
				pinctrl-names = "default";
				pinctrl-0 = <0x17>;
				clock-frequency = <0x61a80>;
				linux,phandle = <0xce>;
				phandle = <0xce>;

				gt9xx@5d {
					compatible = "goodix,gt9xx";
					status = "disabled";
					reg = <0x5d>;
					reset-gpio = <0x16 0x0a 0x00>;
					irq-gpio = <0x16 0x04 0x00>;
				};

				ftxx@38 {
					compatible = "focaltech,fts";
					status = "disabled";
					reg = <0x38>;
					reset-gpio = <0x16 0x0a 0x00>;
					irq-gpio = <0x16 0x04 0x00>;
					x_max = <0x258>;
					y_max = <0x400>;
					max-touch-number = <0x0a>;
				};
			};

			i2c@1e000 {
				compatible = "amlogic,meson-g12a-i2c";
				status = "disabled";
				reg = <0x00 0x1e000 0x00 0x20>;
				interrupts = <0x00 0xd6 0x01 0x00 0x5c 0x01>;
				#address-cells = <0x01>;
				#size-cells = <0x00>;
				clocks = <0x02 0x2a>;
				clock-names = "clk_i2c";
				linux,phandle = <0xcf>;
				phandle = <0xcf>;
			};

			i2c@1d000 {
				compatible = "amlogic,meson-g12a-i2c";
				status = "disabled";
				reg = <0x00 0x1d000 0x00 0x20>;
				interrupts = <0x00 0xd7 0x01 0x00 0x5e 0x01>;
				#address-cells = <0x01>;
				#size-cells = <0x00>;
				clocks = <0x02 0x2a>;
				clock-names = "clk_i2c";
				linux,phandle = <0xd0>;
				phandle = <0xd0>;
			};

			i2c@1c000 {
				compatible = "amlogic,meson-g12a-i2c";
				status = "ok";
				reg = <0x00 0x1c000 0x00 0x20>;
				interrupts = <0x00 0x27 0x01 0x00 0x5f 0x01>;
				#address-cells = <0x01>;
				#size-cells = <0x00>;
				clocks = <0x02 0x2a>;
				clock-names = "clk_i2c";
				pinctrl-names = "default";
				pinctrl-0 = <0x18>;
				clock-frequency = <0x186a0>;
				linux,phandle = <0xd1>;
				phandle = <0xd1>;

				ad82584f_62@62 {
					compatible = "ESMT, ad82584f";
					#sound-dai-cells = <0x00>;
					reg = <0x31>;
					status = "disabled";
					reset_pin = <0x16 0x37 0x00>;
					linux,phandle = <0xd2>;
					phandle = <0xd2>;
				};

				tas5707_36@36 {
					compatible = "ti,tas5707";
					#sound-dai-cells = <0x00>;
					reg = <0x1b>;
					status = "disabled";
					reset_pin = <0x16 0x37 0x00>;
					linux,phandle = <0xd3>;
					phandle = <0xd3>;
				};

				bl_extern_i2c {
					compatible = "amlogic, bl_extern_i2c";
					status = "disabled";
					reg = <0x2c>;
					dev_name = "lp8556";
				};
			};

			spi@13000 {
				compatible = "amlogic,meson-g12a-spicc";
				reg = <0x00 0x13000 0x00 0x44>;
				interrupts = <0x00 0x51 0x04>;
				clocks = <0x02 0x29 0x02 0xcd>;
				clock-names = "core\0comp";
				#address-cells = <0x01>;
				#size-cells = <0x00>;
				status = "disabled";
				linux,phandle = <0xd4>;
				phandle = <0xd4>;
			};

			spi@15000 {
				compatible = "amlogic,meson-g12a-spicc";
				reg = <0x00 0x15000 0x00 0x44>;
				interrupts = <0x00 0x5a 0x04>;
				clocks = <0x02 0x2f 0x02 0xd1>;
				clock-names = "core\0comp";
				#address-cells = <0x01>;
				#size-cells = <0x00>;
				status = "disabled";
				linux,phandle = <0xd5>;
				phandle = <0xd5>;
			};
		};

		aobus@ff800000 {
			compatible = "simple-bus";
			reg = <0x00 0xff800000 0x00 0xb000>;
			#address-cells = <0x02>;
			#size-cells = <0x02>;
			ranges = <0x00 0x00 0x00 0xff800000 0x00 0xb000>;
			linux,phandle = <0xd6>;
			phandle = <0xd6>;

			cpu_version {
				reg = <0x00 0x220 0x00 0x04>;
			};

			clock-controller@0 {
				compatible = "amlogic,g12a-aoclkc";
				#clock-cells = <0x01>;
				reg = <0x00 0x00 0x00 0x320>;
				linux,phandle = <0xd7>;
				phandle = <0xd7>;
			};

			pwm@7000 {
				compatible = "amlogic,g12a-ao-pwm";
				reg = <0x00 0x7000 0x00 0x20>;
				#pwm-cells = <0x03>;
				clocks = <0x14 0x14 0x14 0x14>;
				clock-names = "clkin0\0clkin1\0clkin2\0clkin3";
				status = "disabled";
				linux,phandle = <0xd8>;
				phandle = <0xd8>;
			};

			pwm@2000 {
				compatible = "amlogic,g12a-ao-pwm";
				reg = <0x00 0x2000 0x00 0x20>;
				#pwm-cells = <0x03>;
				clocks = <0x14 0x14 0x14 0x14>;
				clock-names = "clkin0\0clkin1\0clkin2\0clkin3";
				status = "okay";
				linux,phandle = <0x55>;
				phandle = <0x55>;
			};

			i2c@5000 {
				compatible = "amlogic,meson-g12a-i2c";
				status = "disabled";
				reg = <0x00 0x5000 0x00 0x20>;
				interrupts = <0x00 0xc3 0x01 0x00 0xc9 0x01>;
				#address-cells = <0x01>;
				#size-cells = <0x00>;
				clocks = <0x02 0x2a>;
				clock-names = "clk_i2c";
				linux,phandle = <0xd9>;
				phandle = <0xd9>;
			};

			i2c_slave@6000 {
				compatible = "amlogic, meson-i2c-slave";
				status = "disabled";
				reg = <0x00 0x6000 0x00 0x20>;
				interrupts = <0x00 0xc2 0x01>;
				pinctrl-names = "default";
				pinctrl-0 = <0x19>;
				linux,phandle = <0xda>;
				phandle = <0xda>;
			};

			serial@3000 {
				compatible = "amlogic, meson-uart";
				reg = <0x00 0x3000 0x00 0x18>;
				interrupts = <0x00 0xc1 0x01>;
				status = "okay";
				clocks = <0x14>;
				clock-names = "clk_uart";
				xtal_tick_en = <0x02>;
				fifosize = <0x40>;
				pinctrl-names = "default";
				support-sysrq = <0x00>;
				linux,phandle = <0xdb>;
				phandle = <0xdb>;
			};

			serial@4000 {
				compatible = "amlogic, meson-uart";
				reg = <0x00 0x4000 0x00 0x18>;
				interrupts = <0x00 0xc5 0x01>;
				status = "disabled";
				clocks = <0x14>;
				clock-names = "clk_uart";
				fifosize = <0x40>;
				pinctrl-names = "default";
				pinctrl-0 = <0x1a>;
				linux,phandle = <0xdc>;
				phandle = <0xdc>;
			};
		};

		periphs@ff634400 {
			compatible = "simple-bus";
			reg = <0x00 0xff634400 0x00 0x400>;
			#address-cells = <0x02>;
			#size-cells = <0x02>;
			ranges = <0x00 0x00 0x00 0xff634400 0x00 0x400>;
			linux,phandle = <0xdd>;
			phandle = <0xdd>;
		};

		hiubus@ff63c000 {
			compatible = "simple-bus";
			reg = <0x00 0xff63c000 0x00 0x2000>;
			#address-cells = <0x02>;
			#size-cells = <0x02>;
			ranges = <0x00 0x00 0x00 0xff63c000 0x00 0x2000>;
			linux,phandle = <0xde>;
			phandle = <0xde>;

			clock-controller@0 {
				compatible = "amlogic,g12a-clkc";
				#clock-cells = <0x01>;
				reg = <0x00 0x00 0x00 0x320>;
				linux,phandle = <0x02>;
				phandle = <0x02>;
			};
		};

		ion_dev {
			compatible = "amlogic, ion_dev";
			memory-region = <0x1b>;
		};

		audiobus@0xff642000 {
			compatible = "amlogic, audio-controller\0simple-bus";
			reg = <0x00 0xff642000 0x00 0x2000>;
			#address-cells = <0x02>;
			#size-cells = <0x02>;
			ranges = <0x00 0x00 0x00 0xff642000 0x00 0x2000>;
			linux,phandle = <0xdf>;
			phandle = <0xdf>;

			audio_clocks {
				compatible = "amlogic, g12a-audio-clocks";
				#clock-cells = <0x01>;
				reg = <0x00 0x00 0x00 0xb0>;
				linux,phandle = <0x1c>;
				phandle = <0x1c>;
			};

			ddr_manager {
				compatible = "amlogic, g12a-audio-ddr-manager";
				interrupts = <0x00 0x94 0x01 0x00 0x95 0x01 0x00 0x96 0x01 0x00 0x98 0x01 0x00 0x99 0x01 0x00 0x9a 0x01>;
				interrupt-names = "toddr_a\0toddr_b\0toddr_c\0frddr_a\0frddr_b\0frddr_c";
			};

			tdma {
				compatible = "amlogic, g12a-snd-tdma";
				#sound-dai-cells = <0x00>;
				dai-tdm-lane-slot-mask-in = <0x00 0x01>;
				dai-tdm-lane-slot-mask-out = <0x01 0x00>;
				dai-tdm-clk-sel = <0x00>;
				clocks = <0x1c 0x17 0x02 0x0c>;
				clock-names = "mclk\0clk_srcpll";
				pinctrl-names = "tdm_pins";
				pinctrl-0 = <0x1d>;
				linux,phandle = <0x8f>;
				phandle = <0x8f>;
			};

			tdmb {
				compatible = "amlogic, g12a-snd-tdmb";
				#sound-dai-cells = <0x00>;
				dai-tdm-lane-slot-mask-in = <0x00 0x01 0x00 0x00>;
				dai-tdm-lane-slot-mask-out = <0x01 0x00 0x00 0x00>;
				dai-tdm-clk-sel = <0x01>;
				clocks = <0x1c 0x18 0x02 0x0d 0x02 0x0c>;
				clock-names = "mclk\0clk_srcpll\0samesource_sysclk";
				pinctrl-names = "tdm_pins";
				pinctrl-0 = <0x1e 0x1f 0x20>;
				samesource_sel = <0x03>;
				linux,phandle = <0x92>;
				phandle = <0x92>;
			};

			tdmc {
				compatible = "amlogic, g12a-snd-tdmc";
				#sound-dai-cells = <0x00>;
				dai-tdm-lane-slot-mask-in = <0x00 0x01 0x00 0x00>;
				#dai-tdm-lane-slot-mask-out = <0x01 0x00 0x01 0x01>;
				#dai-tdm-lane-oe-slot-mask-in = <0x00 0x00 0x00 0x00>;
				dai-tdm-lane-oe-slot-mask-out = <0x01 0x00 0x00 0x00>;
				dai-tdm-clk-sel = <0x02>;
				clocks = <0x1c 0x19 0x02 0x0e>;
				clock-names = "mclk\0clk_srcpll";
				pinctrl-names = "tdm_pins";
				pinctrl-0 = <0x21 0x22>;
				linux,phandle = <0x93>;
				phandle = <0x93>;
			};

			i2s2hdmi {
				compatible = "amlogic, g12a-snd-tdmc";
				#sound-dai-cells = <0x00>;
				dai-tdm-lane-slot-mask-out = <0x01 0x01 0x01 0x01>;
				dai-tdm-clk-sel = <0x02>;
				clocks = <0x1c 0x19 0x02 0x0e>;
				clock-names = "mclk\0clk_srcpll";
				i2s2hdmi = <0x01>;
				status = "disabled";
				linux,phandle = <0xe0>;
				phandle = <0xe0>;
			};

			spdif {
				compatible = "amlogic, g12a-snd-spdif-a";
				#sound-dai-cells = <0x00>;
				clocks = <0x02 0x0c 0x02 0x04 0x1c 0x10 0x1c 0x11 0x1c 0x1d 0x1c 0x1e>;
				clock-names = "sysclk\0fixed_clk\0gate_spdifin\0gate_spdifout\0clk_spdifin\0clk_spdifout";
				interrupts = <0x00 0x97 0x01>;
				interrupt-names = "irq_spdifin";
				pinctrl-names = "spdif_pins";
				pinctrl-0 = <0x23>;
				status = "okay";
				linux,phandle = <0x95>;
				phandle = <0x95>;
			};

			spdif_b {
				compatible = "amlogic, g12a-snd-spdif-b";
				#sound-dai-cells = <0x00>;
				clocks = <0x02 0x0c 0x1c 0x15 0x1c 0x21>;
				clock-names = "sysclk\0gate_spdifout\0clk_spdifout";
				status = "okay";
				linux,phandle = <0x96>;
				phandle = <0x96>;
			};

			pdm {
				compatible = "amlogic, g12a-snd-pdm";
				#sound-dai-cells = <0x00>;
				clocks = <0x1c 0x01 0x02 0x03 0x02 0x0f 0x1c 0x1f 0x1c 0x20>;
				clock-names = "gate\0sysclk_srcpll\0dclk_srcpll\0pdm_dclk\0pdm_sysclk";
				pinctrl-names = "pdm_pins";
				pinctrl-0 = <0x24>;
				filter_mode = <0x01>;
				status = "okay";
				linux,phandle = <0x94>;
				phandle = <0x94>;
			};

			loopback {
				compatible = "amlogic, snd-loopback";
				lb_mode = <0x00>;
				datain_src = <0x04>;
				datain_chnum = <0x08>;
				datain_chmask = <0x3f>;
				datalb_src = <0x02>;
				datalb_chnum = <0x08>;
				datalb_chmask = <0x03>;
				status = "okay";
				linux,phandle = <0x8c>;
				phandle = <0x8c>;
			};

			resample {
				compatible = "amlogic, g12a-resample";
				clocks = <0x02 0x0f 0x1c 0x1c 0x1c 0x24>;
				clock-names = "resample_pll\0resample_src\0resample_clk";
				resample_module = <0x04>;
				status = "okay";
				linux,phandle = <0xe1>;
				phandle = <0xe1>;
			};

			pwrdet {
				compatible = "amlogic, g12a-power-detect";
				interrupts = <0x00 0x9b 0x01>;
				interrupt-names = "pwrdet_irq";
				pwrdet_src = <0x04>;
				hi_th = <0x70000>;
				lo_th = <0x16000>;
				status = "okay";
				linux,phandle = <0xe2>;
				phandle = <0xe2>;
			};
		};
	};

	rc@0xff808040 {
		compatible = "amlogic, aml_remote";
		dev_name = "meson-remote";
		reg = <0x00 0xff808040 0x00 0x44 0x00 0xff808000 0x00 0x20>;
		status = "okay";
		protocol = <0x01>;
		led_blink = <0x01>;
		led_blink_frq = <0x64>;
		interrupts = <0x00 0xc4 0x01>;
		pinctrl-names = "default";
		pinctrl-0 = <0x25>;
		map = <0x26>;
		max_frame_time = <0xc8>;
		linux,phandle = <0xe3>;
		phandle = <0xe3>;
	};

	custom_maps {
		mapnum = <0x03>;
		map0 = <0x27>;
		map1 = <0x28>;
		map2 = <0x29>;
		linux,phandle = <0x26>;
		phandle = <0x26>;

		map_0 {
			mapname = "amlogic-remote-1";
			customcode = <0xfe01>;
			release_delay = <0x39>;
			size = <0x0c>;
			keymap = <0x1e000b 0x74 0x590067 0x51006c 0x540069 0x55001c 0x15006a 0x40068 0x6006d 0x410071 0x5c0066 0x19009e>;
			linux,phandle = <0x27>;
			phandle = <0x27>;
		};

		map_1 {
			mapname = "amlogic-remote-2";
			customcode = <0x4a69>;
			release_delay = <0x50>;
			size = <0x15>;
			keymap = <0x70000a 0x710009 0x720008 0x730007 0x740006 0x750005 0x760002 0x77000b 0x78001e 0x790030 0x7a002e 0x7b0020 0x7c0012 0x7d0040 0x7e0041 0x7f0042 0x800043 0x810044 0x820045 0x830003 0x840004>;
			linux,phandle = <0x28>;
			phandle = <0x28>;
		};

		map_2 {
			mapname = "amlogic-remote-3";
			customcode = <0xbd02>;
			release_delay = <0x50>;
			size = <0x11>;
			keymap = <0xca0067 0xd2006c 0x990069 0xc1006a 0xce0061 0x450074 0xc50085 0x800071 0xd0000f 0xd6007d 0x950066 0xdd0068 0x8c006d 0x890083 0x9c0082 0x9a0078 0xcd0079>;
			linux,phandle = <0x29>;
			phandle = <0x29>;
		};
	};

	encryption_chip {
		compatible = "sei,encryption_chip";
		dev_name = "encryption_chip";
		i2c_num = <0x03>;
		status = "okay";
	};

	serial@ffd24000 {
		compatible = "amlogic, meson-uart";
		reg = <0x00 0xffd24000 0x00 0x18>;
		interrupts = <0x00 0x1a 0x01>;
		status = "okay";
		clocks = <0x14 0x02 0x2e>;
		clock-names = "clk_uart\0clk_gate";
		fifosize = <0x80>;
		pinctrl-names = "default";
		pinctrl-0 = <0x2a>;
		linux,phandle = <0xe4>;
		phandle = <0xe4>;
	};

	serial@ffd23000 {
		compatible = "amlogic, meson-uart";
		reg = <0x00 0xffd23000 0x00 0x18>;
		interrupts = <0x00 0x4b 0x01>;
		status = "disabled";
		clocks = <0x14 0x02 0x3c>;
		clock-names = "clk_uart\0clk_gate";
		fifosize = <0x40>;
		pinctrl-names = "default";
		pinctrl-0 = <0x2b>;
		linux,phandle = <0xe5>;
		phandle = <0xe5>;
	};

	serial@ffd22000 {
		compatible = "amlogic, meson-uart";
		reg = <0x00 0xffd22000 0x00 0x18>;
		interrupts = <0x00 0x5d 0x01>;
		status = "disabled";
		clocks = <0x14 0x02 0x3c>;
		clock-names = "clk_uart\0clk_gate";
		fifosize = <0x40>;
		pinctrl-names = "default";
		pinctrl-0 = <0x2c>;
		linux,phandle = <0xe6>;
		phandle = <0xe6>;
	};

	pcieA@fc000000 {
		compatible = "amlogic, amlogic-pcie-v2\0snps,dw-pcie";
		reg = <0x00 0xfc000000 0x00 0x400000 0x00 0xff648000 0x00 0x2000 0x00 0xfc400000 0x00 0x200000 0x00 0xff646000 0x00 0x2000 0x00 0xffd01080 0x00 0x10>;
		reg-names = "elbi\0cfg\0config\0phy\0reset";
		interrupts = <0x00 0xdd 0x00>;
		#interrupt-cells = <0x01>;
		bus-range = <0x00 0xff>;
		#address-cells = <0x03>;
		#size-cells = <0x02>;
		interrupt-map-mask = <0x00 0x00 0x00 0x00>;
		interrupt-map = <0x00 0x00 0x00 0x00 0x01 0x00 0xdf 0x01>;
		device_type = "pci";
		ranges = <0x81000000 0x00 0x00 0x00 0xfc600000 0x00 0x100000 0x82000000 0x00 0xfc700000 0x00 0xfc700000 0x00 0x1900000>;
		num-lanes = <0x01>;
		pcie-num = <0x01>;
		clocks = <0x02 0x18 0x02 0x3f 0x02 0x42>;
		clock-names = "pcie_refpll\0pcie\0pcie_phy";
		gpio-type = <0x02>;
		pcie-apb-rst-bit = <0x0f>;
		pcie-phy-rst-bit = <0x0e>;
		pcie-ctrl-a-rst-bit = <0x0c>;
		status = "disable";
		reset-gpio = <0x16 0x49 0x00>;
		linux,phandle = <0xe7>;
		phandle = <0xe7>;
	};

	amhdmitx {
		compatible = "amlogic, amhdmitx";
		dev_name = "amhdmitx";
		status = "okay";
		vend-data = <0x2d>;
		pinctrl-names = "default\0hdmitx_i2c";
		pinctrl-0 = <0x2e 0x2f>;
		pinctrl-1 = <0x30 0x31>;
		clocks = <0x02 0x55 0x02 0x4e 0x02 0x4f 0x02 0x95 0x02 0x8c>;
		clock-names = "venci_top_gate\0venci_0_gate\0venci_1_gate\0hdmi_vapb_clk\0hdmi_vpu_clk";
		interrupts = <0x00 0x39 0x01>;
		interrupt-names = "hdmitx_hpd";
		ic_type = <0x0a>;
		linux,phandle = <0xe8>;
		phandle = <0xe8>;

		vend_data {
			vendor_name = "Amlogic";
			vendor_id = <0x00>;
			linux,phandle = <0x2d>;
			phandle = <0x2d>;
		};
	};

	aocec {
		compatible = "amlogic, aocec-g12a";
		device_name = "aocec";
		status = "okay";
		vendor_name = "Amlogic";
		vendor_id = <0x00>;
		product_desc = "G12A";
		cec_osd_string = "AML_MBOX";
		cec_version = <0x05>;
		port_num = <0x01>;
		ee_cec;
		arc_port_mask = <0x02>;
		interrupts = <0x00 0xcb 0x01 0x00 0xc7 0x01>;
		interrupt-names = "hdmi_aocecb\0hdmi_aocec";
		pinctrl-names = "default\0hdmitx_aocecb\0cec_pin_sleep";
		pinctrl-0 = <0x32>;
		pinctrl-1 = <0x33>;
		pinctrl-2 = <0x33>;
		reg = <0x00 0xff80023c 0x00 0x04 0x00 0xff800000 0x00 0x400 0x00 0xff634400 0x00 0x26>;
		reg-names = "ao_exit\0ao\0periphs";
		linux,phandle = <0xe9>;
		phandle = <0xe9>;
	};

	vdin0 {
		compatible = "amlogic, vdin";
		dev_name = "vdin0";
		status = "okay";
		reserve-iomap = "true";
		flag_cma = <0x00>;
		interrupts = <0x00 0x53 0x01>;
		rdma-irq = <0x02>;
		vdin_id = <0x00>;
		memory-region = <0x34>;
		tv_bit_mode = <0x15>;
		linux,phandle = <0xea>;
		phandle = <0xea>;
	};

	vdin1 {
		compatible = "amlogic, vdin";
		dev_name = "vdin1";
		status = "okay";
		reserve-iomap = "true";
		flag_cma = <0x00>;
		interrupts = <0x00 0x55 0x01>;
		rdma-irq = <0x04>;
		vdin_id = <0x01>;
		memory-region = <0x35>;
		tv_bit_mode = <0x01>;
		linux,phandle = <0xeb>;
		phandle = <0xeb>;
	};

	vout {
		compatible = "amlogic, vout";
		dev_name = "vout";
		status = "okay";
	};

	vout2 {
		compatible = "amlogic, vout2";
		dev_name = "vout";
		status = "okay";
		clocks = <0x02 0xc4 0x02 0xc9>;
		clock-names = "vpu_clkc0\0vpu_clkc";
	};

	vdac {
		compatible = "amlogic, vdac-g12a";
		status = "okay";
	};

	canvas {
		compatible = "amlogic, meson, canvas";
		dev_name = "amlogic-canvas";
		status = "okay";
		reg = <0x00 0xff638000 0x00 0x2000>;
		linux,phandle = <0xec>;
		phandle = <0xec>;
	};

	ge2d {
		compatible = "amlogic, ge2d-g12a";
		dev_name = "ge2d";
		status = "okay";
		interrupts = <0x00 0x92 0x01>;
		interrupt-names = "ge2d";
		clocks = <0x02 0x95 0x02 0x3d 0x02 0x96>;
		clock-names = "clk_vapb_0\0clk_ge2d\0clk_ge2d_gate";
		reg = <0x00 0xff940000 0x00 0x10000>;
	};

	meson-amvideom {
		compatible = "amlogic, amvideom";
		dev_name = "amvideom";
		status = "okay";
		interrupts = <0x00 0x03 0x01>;
		interrupt-names = "vsync";
	};

	codec_io {
		compatible = "amlogic, codec_io";
		status = "okay";
		#address-cells = <0x02>;
		#size-cells = <0x02>;
		ranges;
		linux,phandle = <0xed>;
		phandle = <0xed>;

		io_cbus_base {
			reg = <0x00 0xffd00000 0x00 0x100000>;
		};

		io_dos_base {
			reg = <0x00 0xff620000 0x00 0x10000>;
		};

		io_hiubus_base {
			reg = <0x00 0xff63c000 0x00 0x2000>;
		};

		io_aobus_base {
			reg = <0x00 0xff800000 0x00 0x10000>;
		};

		io_vcbus_base {
			reg = <0x00 0xff900000 0x00 0x40000>;
		};

		io_dmc_base {
			reg = <0x00 0xff638000 0x00 0x2000>;
		};

		io_efuse_base {
			reg = <0x00 0xff630000 0x00 0x2000>;
		};
	};

	mesonstream {
		compatible = "amlogic, codec, streambuf";
		dev_name = "mesonstream";
		status = "okay";
		clocks = <0x02 0x40 0x02 0x39 0x02 0x43 0x02 0x22 0x02 0xa5 0x02 0xae 0x02 0xb7 0x02 0xc0>;
		clock-names = "parser_top\0demux\0ahbarb0\0vdec\0clk_vdec_mux\0clk_hcodec_mux\0clk_hevc_mux\0clk_hevcb_mux";
	};

	vdec {
		compatible = "amlogic, vdec";
		dev_name = "vdec.0";
		status = "okay";
		interrupts = <0x00 0x03 0x01 0x00 0x17 0x01 0x00 0x20 0x01 0x00 0x2b 0x01 0x00 0x2c 0x01 0x00 0x2d 0x01>;
		interrupt-names = "vsync\0demux\0parser\0mailbox_0\0mailbox_1\0mailbox_2";
	};

	vcodec_dec {
		compatible = "amlogic, vcodec-dec";
		dev_name = "aml-vcodec-dec";
		status = "okay";
	};

	amvenc_avc {
		compatible = "amlogic, amvenc_avc";
		dev_name = "amvenc_avc";
		status = "okay";
		interrupts = <0x00 0x2d 0x01>;
		interrupt-names = "mailbox_2";
	};

	hevc_enc {
		compatible = "cnm, HevcEnc";
		dev_name = "HevcEnc";
		status = "okay";
		interrupts = <0x00 0xbb 0x01>;
		interrupt-names = "wave420l_irq";
		#address-cells = <0x02>;
		#size-cells = <0x02>;
		ranges;

		io_reg_base {
			reg = <0x00 0xff610000 0x00 0x4000>;
		};
	};

	rdma {
		compatible = "amlogic, meson, rdma";
		dev_name = "amlogic-rdma";
		status = "okay";
		interrupts = <0x00 0x59 0x01>;
		interrupt-names = "rdma";
	};

	meson-fb {
		compatible = "amlogic, meson-g12a";
		memory-region = <0x36>;
		dev_name = "meson-fb";
		status = "okay";
		interrupts = <0x00 0x03 0x01 0x00 0x38 0x01 0x00 0x59 0x01>;
		interrupt-names = "viu-vsync\0viu2-vsync\0rdma";
		display_mode_default = "1080p60hz";
		scale_mode = <0x01>;
		display_size_default = <0x780 0x438 0x780 0x870 0x20>;
		clocks = <0x02 0xc9>;
		clock-names = "vpu_clkc";
		mem_size = <0x800000 0x1980000 0x100000 0x100000 0x800000>;
		logo_addr = "0x3f800000";
		mem_alloc = <0x00>;
		pxp_mode = <0x00>;
		linux,phandle = <0xee>;
		phandle = <0xee>;
	};

	meson-irblaster {
		compatible = "amlogic, meson_irblaster";
		reg = <0x00 0xff80014c 0x00 0x10 0x00 0xff800040 0x00 0x04>;
		pinctrl-names = "default";
		pinctrl-0 = <0x37>;
		interrupts = <0x00 0xc6 0x01>;
		status = "okay";
		linux,phandle = <0xef>;
		phandle = <0xef>;
	};

	emmc@ffe07000 {
		status = "okay";
		compatible = "amlogic, meson-mmc-g12a";
		reg = <0x00 0xffe07000 0x00 0x800>;
		interrupts = <0x00 0xbf 0x01>;
		pinctrl-names = "emmc_clk_cmd_pins\0emmc_all_pins";
		pinctrl-0 = <0x38>;
		pinctrl-1 = <0x39 0x3a>;
		clocks = <0x02 0x35 0x02 0x72 0x02 0x02 0x02 0x05 0x14>;
		clock-names = "core\0clkin0\0clkin1\0clkin2\0xtal";
		bus-width = <0x08>;
		cap-sd-highspeed;
		cap-mmc-highspeed;
		max-frequency = <0xbebc200>;
		non-removable;
		disable-wp;
		linux,phandle = <0xf0>;
		phandle = <0xf0>;

		emmc {
			pinname = "emmc";
			ocr_avail = <0x200080>;
			tx_delay = <0x00>;
			co_phase = <0x03>;
			max_req_size = <0x20000>;
			gpio_dat3 = <0x16 0x1d 0x00>;
			hw_reset = <0x16 0x23 0x00>;
			card_type = <0x01>;
			caps = "MMC_CAP_8_BIT_DATA\0MMC_CAP_MMC_HIGHSPEED\0MMC_CAP_SD_HIGHSPEED\0MMC_CAP_NONREMOVABLE\0MMC_CAP_HW_RESET\0MMC_CAP_ERASE\0MMC_CAP_CMD23";
			caps2 = "MMC_CAP2_HS200";
			f_min = <0x61a80>;
			f_max = <0xbebc200>;
		};
	};

	sd1@ffe05000 {
		status = "disabled";
		compatible = "amlogic, meson-mmc-g12a";
		reg = <0x00 0xffe05000 0x00 0x800>;
		interrupts = <0x00 0xbe 0x01>;
		pinctrl-names = "sd_all_pins\0sd_clk_cmd_pins\0sd_1bit_pins\0sd_clk_cmd_uart_pins\0sd_1bit_uart_pins\0sd_to_ao_uart_pins\0ao_to_sd_uart_pins\0sd_to_ao_jtag_pins\0ao_to_sd_jtag_pins";
		pinctrl-0 = <0x3b>;
		pinctrl-1 = <0x3c>;
		pinctrl-2 = <0x3d>;
		pinctrl-3 = <0x3e 0x3c 0x3f>;
		pinctrl-4 = <0x3e 0x3d 0x3f>;
		pinctrl-5 = <0x3b 0x40>;
		pinctrl-6 = <0x3e 0x3f>;
		pinctrl-7 = <0x3b 0x40>;
		pinctrl-8 = <0x3e 0x3f>;
		clocks = <0x02 0x34 0x02 0x6e 0x02 0x02 0x02 0x05 0x14>;
		clock-names = "core\0clkin0\0clkin1\0clkin2\0xtal";
		bus-width = <0x04>;
		cap-sd-highspeed;
		cap-mmc-highspeed;
		max-frequency = <0x5f5e100>;
		disable-wp;
		linux,phandle = <0xf1>;
		phandle = <0xf1>;

		sd {
			pinname = "sd";
			ocr_avail = <0x200080>;
			max_req_size = <0x20000>;
			gpio_dat3 = <0x16 0x2d 0x00>;
			jtag_pin = <0x16 0x2a 0x00>;
			gpio_cd = <0x16 0x30 0x00>;
			card_type = <0x05>;
			caps = "MMC_CAP_4_BIT_DATA\0MMC_CAP_MMC_HIGHSPEED\0MMC_CAP_SD_HIGHSPEED";
			f_min = <0x61a80>;
			f_max = <0x2faf080>;
		};
	};

	sd2@ffe05000 {
		status = "disabled";
		compatible = "amlogic, meson-mmc-g12a";
		reg = <0x00 0xffe05000 0x00 0x800>;
		interrupts = <0x00 0xbe 0x04>;
		pinctrl-names = "sd_all_pins\0sd_clk_cmd_pins\0sd_1bit_pins\0sd_clk_cmd_uart_pins\0sd_1bit_uart_pins\0sd_to_ao_uart_pins\0ao_to_sd_uart_pins\0sd_to_ao_jtag_pins\0ao_to_sd_jtag_pins\0sdio_noclr_all_pins\0sdio_noclr_clk_cmd_pins\0sdio_all_pins\0sdio_clk_cmd_pins";
		pinctrl-0 = <0x41 0x3b>;
		pinctrl-1 = <0x41 0x3c>;
		pinctrl-2 = <0x41 0x3d>;
		pinctrl-3 = <0x41 0x3e 0x3c 0x3f>;
		pinctrl-4 = <0x41 0x3e 0x3d 0x3f>;
		pinctrl-5 = <0x41 0x3b 0x40>;
		pinctrl-6 = <0x42 0x3e 0x43 0x3f>;
		pinctrl-7 = <0x42 0x44 0x40>;
		pinctrl-8 = <0x42 0x3e 0x43 0x3f>;
		pinctrl-9 = <0x43 0x42 0x45>;
		pinctrl-10 = <0x43 0x42 0x46>;
		pinctrl-11 = <0x44 0x42 0x45>;
		pinctrl-12 = <0x44 0x42 0x46>;
		clocks = <0x02 0x34 0x02 0x6e 0x02 0x02 0x02 0x05 0x14>;
		clock-names = "core\0clkin0\0clkin1\0clkin2\0xtal";
		bus-width = <0x04>;
		cap-sd-highspeed;
		cap-mmc-highspeed;
		max-frequency = <0x5f5e100>;
		disable-wp;
		linux,phandle = <0xf2>;
		phandle = <0xf2>;

		sd {
			pinname = "sd";
			ocr_avail = <0x200080>;
			max_req_size = <0x20000>;
			gpio_dat3 = <0x16 0x2d 0x00>;
			jtag_pin = <0x16 0x2a 0x00>;
			gpio_cd = <0x16 0x30 0x00>;
			card_type = <0x05>;
			caps = "MMC_CAP_4_BIT_DATA\0MMC_CAP_MMC_HIGHSPEED\0MMC_CAP_SD_HIGHSPEED";
			f_min = <0x61a80>;
			f_max = <0x2faf080>;
		};

		sdio {
			pinname = "sdio";
			ocr_avail = <0x200080>;
			max_req_size = <0x20000>;
			card_type = <0x03>;
			caps = "MMC_CAP_4_BIT_DATA\0MMC_CAP_MMC_HIGHSPEED\0MMC_CAP_SD_HIGHSPEED\0MMC_CAP_NONREMOVABLE\0MMC_CAP_UHS_SDR12\0MMC_CAP_UHS_SDR25\0MMC_CAP_UHS_SDR50\0MMC_CAP_UHS_SDR104\0MMC_PM_KEEP_POWER\0MMC_CAP_SDIO_IRQ";
			f_min = <0x61a80>;
			f_max = <0xa21fe80>;
		};
	};

	sdio@ffe03000 {
		status = "disabled";
		compatible = "amlogic, meson-mmc-g12a";
		reg = <0x00 0xffe03000 0x00 0x800>;
		interrupts = <0x00 0xbd 0x04>;
		pinctrl-names = "sdio_all_pins\0sdio_clk_cmd_pins";
		pinctrl-0 = <0x47>;
		pinctrl-1 = <0x48>;
		clocks = <0x02 0x33 0x02 0x6a 0x02 0x02 0x02 0x05 0x14>;
		clock-names = "core\0clkin0\0clkin1\0clkin2\0xtal";
		bus-width = <0x04>;
		cap-sd-highspeed;
		cap-mmc-highspeed;
		max-frequency = <0x5f5e100>;
		disable-wp;
		linux,phandle = <0xf3>;
		phandle = <0xf3>;

		sdio {
			pinname = "sdio";
			ocr_avail = <0x200080>;
			max_req_size = <0x400>;
			card_type = <0x03>;
			dmode = "pio";
			caps = "MMC_CAP_4_BIT_DATA\0MMC_CAP_MMC_HIGHSPEED\0MMC_CAP_SD_HIGHSPEED\0MMC_CAP_NONREMOVABLE\0MMC_CAP_UHS_SDR12\0MMC_CAP_UHS_SDR25\0MMC_CAP_UHS_SDR50\0MMC_CAP_UHS_SDR104\0MMC_PM_KEEP_POWER\0MMC_CAP_SDIO_IRQ";
			f_min = <0x61a80>;
			f_max = <0xbebc200>;
		};
	};

	nfc@0 {
		compatible = "amlogic, aml_mtd_nand";
		dev_name = "mtdnand";
		status = "disabled";
		reg = <0x00 0xffe07800 0x00 0x200>;
		interrupts = <0x00 0x22 0x01>;
		pinctrl-names = "nand_rb_mod\0nand_norb_mod\0nand_cs_only";
		pinctrl-0 = <0x49>;
		pinctrl-1 = <0x49>;
		pinctrl-2 = <0x4a>;
		clocks = <0x02 0x35 0x02 0x72>;
		clock-names = "core\0clkin";
		device_id = <0x00>;
		bl_mode = <0x01>;
		fip_copies = <0x04>;
		fip_size = <0x200000>;
		nand_clk_ctrl = <0xffe07000>;
		plat-names = "bootloader\0nandnormal";
		plat-num = <0x02>;
		plat-part-0 = <0x4b>;
		plat-part-1 = <0x4c>;
		linux,phandle = <0xf4>;
		phandle = <0xf4>;

		bootloader {
			enable_pad = "ce0";
			busy_pad = "rb0";
			timming_mode = "mode5";
			bch_mode = "bch8_1k";
			t_rea = <0x14>;
			t_rhoh = <0x0f>;
			chip_num = <0x01>;
			part_num = <0x00>;
			rb_detect = <0x01>;
			linux,phandle = <0x4b>;
			phandle = <0x4b>;
		};

		nandnormal {
			enable_pad = "ce0";
			busy_pad = "rb0";
			timming_mode = "mode5";
			bch_mode = "bch8_1k";
			plane_mode = "twoplane";
			t_rea = <0x14>;
			t_rhoh = <0x0f>;
			chip_num = <0x02>;
			part_num = <0x03>;
			partition = <0x4d>;
			rb_detect = <0x01>;
			linux,phandle = <0x4c>;
			phandle = <0x4c>;
		};

		nand_partition {
			linux,phandle = <0x4d>;
			phandle = <0x4d>;

			tpl {
				offset = <0x00 0x00>;
				size = <0x00 0x00>;
			};

			logo {
				offset = <0x00 0x00>;
				size = <0x00 0x200000>;
			};

			recovery {
				offset = <0x00 0x00>;
				size = <0x00 0x1000000>;
			};

			boot {
				offset = <0x00 0x00>;
				size = <0x00 0x1000000>;
			};

			system {
				offset = <0x00 0x00>;
				size = <0x00 0x4000000>;
			};

			data {
				offset = <0xffffffff 0xffffffff>;
				size = <0x00 0x00>;
			};
		};
	};

	meson-cooldev@0 {
		status = "okay";
		compatible = "amlogic, meson-cooldev";
		device_name = "mcooldev";
		linux,phandle = <0xf5>;
		phandle = <0xf5>;

		cooling_devices {

			cpufreq_cool_cluster0 {
				min_state = <0xf4240>;
				dyn_coeff = <0x73>;
				cluster_id = <0x00>;
				node_name = "cpufreq_cool0";
				device_type = "cpufreq";
			};

			cpucore_cool_cluster0 {
				min_state = <0x01>;
				dyn_coeff = <0x00>;
				cluster_id = <0x00>;
				node_name = "cpucore_cool0";
				device_type = "cpucore";
			};

			gpufreq_cool {
				min_state = <0x190>;
				dyn_coeff = <0x166>;
				gpu_pp = <0x02>;
				cluster_id = <0x00>;
				node_name = "gpufreq_cool0";
				device_type = "gpufreq";
			};

			gpucore_cool {
				min_state = <0x01>;
				dyn_coeff = <0x00>;
				cluster_id = <0x00>;
				node_name = "gpucore_cool0";
				device_type = "gpucore";
			};
		};

		cpufreq_cool0 {
			#cooling-cells = <0x02>;
			linux,phandle = <0x50>;
			phandle = <0x50>;
		};

		cpucore_cool0 {
			#cooling-cells = <0x02>;
			linux,phandle = <0x51>;
			phandle = <0x51>;
		};

		gpufreq_cool0 {
			#cooling-cells = <0x02>;
			linux,phandle = <0x52>;
			phandle = <0x52>;
		};

		gpucore_cool0 {
			#cooling-cells = <0x02>;
			linux,phandle = <0x53>;
			phandle = <0x53>;
		};
	};

	thermal-zones {

		soc_thermal {
			polling-delay = <0x3e8>;
			polling-delay-passive = <0x64>;
			sustainable-power = <0x5b4>;
			thermal-sensors = <0x4e 0x00>;
			linux,phandle = <0xf6>;
			phandle = <0xf6>;

			trips {

				trip-point@0 {
					temperature = <0xea60>;
					hysteresis = <0x1388>;
					type = "passive";
					linux,phandle = <0xf7>;
					phandle = <0xf7>;
				};

				trip-point@1 {
					temperature = <0x124f8>;
					hysteresis = <0x1388>;
					type = "passive";
					linux,phandle = <0x4f>;
					phandle = <0x4f>;
				};

				trip-point@2 {
					temperature = <0x14c08>;
					hysteresis = <0x1388>;
					type = "hot";
					linux,phandle = <0xf8>;
					phandle = <0xf8>;
				};

				trip-point@3 {
					temperature = <0x1adb0>;
					hysteresis = <0x3e8>;
					type = "critical";
					linux,phandle = <0xf9>;
					phandle = <0xf9>;
				};
			};

			cooling-maps {

				cpufreq_cooling_map {
					trip = <0x4f>;
					cooling-device = <0x50 0x00 0x04>;
					contribution = <0x400>;
				};

				cpucore_cooling_map {
					trip = <0x4f>;
					cooling-device = <0x51 0x00 0x03>;
					contribution = <0x400>;
				};

				gpufreq_cooling_map {
					trip = <0x4f>;
					cooling-device = <0x52 0x00 0x04>;
					contribution = <0x400>;
				};

				gpucore_cooling_map {
					trip = <0x4f>;
					cooling-device = <0x53 0x00 0x02>;
					contribution = <0x400>;
				};
			};
		};

		ddr_thermal {
			polling-delay = <0x3e8>;
			polling-delay-passive = <0x64>;
			sustainable-power = <0x866>;
			thermal-sensors = <0x54 0x01>;
			linux,phandle = <0xfa>;
			phandle = <0xfa>;

			trips {

				trip-point@0 {
					temperature = <0xea60>;
					hysteresis = <0x1388>;
					type = "passive";
					linux,phandle = <0xfb>;
					phandle = <0xfb>;
				};

				trip-point@1 {
					temperature = <0x124f8>;
					hysteresis = <0x1388>;
					type = "passive";
					linux,phandle = <0xfc>;
					phandle = <0xfc>;
				};

				trip-point@2 {
					temperature = <0x14c08>;
					hysteresis = <0x1388>;
					type = "hot";
					linux,phandle = <0xfd>;
					phandle = <0xfd>;
				};

				trip-point@3 {
					temperature = <0x1adb0>;
					hysteresis = <0x3e8>;
					type = "critical";
					linux,phandle = <0xfe>;
					phandle = <0xfe>;
				};
			};
		};
	};

	aml_snd_iomap {
		compatible = "amlogic, snd-iomap";
		status = "okay";
		#address-cells = <0x02>;
		#size-cells = <0x02>;
		ranges;

		pdm_bus {
			reg = <0x00 0xff640000 0x00 0x2000>;
		};

		audiobus_base {
			reg = <0x00 0xff642000 0x00 0x2000>;
		};

		audiolocker_base {
			reg = <0x00 0xff64a000 0x00 0x2000>;
		};

		eqdrc_base {
			reg = <0x00 0xff642800 0x00 0x1800>;
		};

		reset_base {
			reg = <0x00 0xffd01000 0x00 0x1000>;
		};
	};

	pwmao_d-regulator {
		compatible = "pwm-regulator";
		pwms = <0x55 0x01 0x4e2 0x00>;
		regulator-name = "vddcpu0";
		regulator-min-microvolt = <0xb0068>;
		regulator-max-microvolt = <0xf9830>;
		regulator-always-on;
		max-duty-cycle = <0x4e2>;
		voltage-table = <0xf9830 0x00 0xf6d38 0x03 0xf4628 0x06 0xf1f18 0x0a 0xef808 0x0d 0xed0f8 0x10 0xea9e8 0x14 0xe82d8 0x17 0xe5bc8 0x1a 0xe34b8 0x1e 0xe0da8 0x21 0xde698 0x24 0xdbf88 0x28 0xd9878 0x2b 0xd7168 0x2e 0xd4a58 0x32 0xd2348 0x35 0xcfc38 0x38 0xcd528 0x3c 0xcae18 0x3f 0xc8708 0x43 0xc5ff8 0x46 0xc38e8 0x49 0xc11d8 0x4c 0xbeac8 0x50 0xbc3b8 0x53 0xb9ca8 0x56 0xb7598 0x5a 0xb4e88 0x5d 0xb2778 0x60 0xb0068 0x64>;
		status = "okay";
		linux,phandle = <0x0e>;
		phandle = <0x0e>;
	};

	ddr_bandwidth {
		compatible = "amlogic, ddr-bandwidth";
		status = "okay";
		reg = <0x00 0xff638000 0x00 0x100 0x00 0xff638c00 0x00 0x100>;
		interrupts = <0x00 0x34 0x01>;
		interrupt-names = "ddr_bandwidth";
	};

	dmc_monitor {
		compatible = "amlogic, dmc_monitor";
		status = "okay";
		reg_base = <0xff639000>;
		interrupts = <0x00 0x33 0x01>;
	};

	defendkey {
		compatible = "amlogic, defendkey";
		reg = <0x00 0xff630218 0x00 0x04>;
		mem_size = <0x00 0x1000>;
		status = "disabled";
		linux,phandle = <0xff>;
		phandle = <0xff>;
	};

	aml_dma {
		compatible = "amlogic,aml_txlx_dma";
		reg = <0x00 0xff63e000 0x00 0x48>;
		interrupts = <0x00 0xb4 0x01>;

		aml_aes {
			compatible = "amlogic,aes_g12a_dma";
			dev_name = "aml_aes_dma";
			status = "okay";
		};

		aml_sha {
			compatible = "amlogic,sha_dma";
			dev_name = "aml_sha_dma";
			status = "okay";
		};
	};

	efuse {
		compatible = "amlogic, efuse";
		read_cmd = <0x82000030>;
		write_cmd = <0x82000031>;
		get_max_cmd = <0x82000033>;
		key = <0x56>;
		clocks = <0x02 0x61>;
		clock-names = "efuse_clk";
		status = "disabled";
		linux,phandle = <0x100>;
		phandle = <0x100>;
	};

	cpu_ver_name {
		compatible = "amlogic, cpu-major-id-g12a";
	};

	firmware {

		android {
			compatible = "android,firmware";

			vbmeta {
				compatible = "android,vbmeta";
				parts = "vbmeta,boot,system,vendor";
				by_name_prefix = "/dev/block";
			};

			fstab {
				compatible = "android,fstab";

				vendor {
					compatible = "android,vendor";
					dev = "/dev/block/vendor";
					type = "ext4";
					mnt_flags = "ro,barrier=1,inode_readahead_blks=8";
					fsmgr_flags = "wait";
				};

				product {
					compatible = "android,product";
					dev = "/dev/block/product";
					type = "ext4";
					mnt_flags = "ro,barrier=1,inode_readahead_blks=8";
					fsmgr_flags = "wait";
				};

				odm {
					compatible = "android,odm";
					dev = "/dev/block/odm";
					type = "ext4";
					mnt_flags = "ro,barrier=1,inode_readahead_blks=8";
					fsmgr_flags = "wait";
				};
			};
		};
	};

	partitions {
		parts = <0x12>;
		part-0 = <0x57>;
		part-1 = <0x58>;
		part-2 = <0x59>;
		part-3 = <0x5a>;
		part-4 = <0x5b>;
		part-5 = <0x5c>;
		part-6 = <0x5d>;
		part-7 = <0x5e>;
		part-8 = <0x5f>;
		part-9 = <0x60>;
		part-10 = <0x61>;
		part-11 = <0x62>;
		part-12 = <0x63>;
		part-13 = <0x64>;
		part-14 = <0x65>;
		part-15 = <0x66>;
		part-16 = <0x67>;
		part-17 = <0x68>;
		linux,phandle = <0x101>;
		phandle = <0x101>;

		logo {
			pname = "logo";
			size = <0x00 0x800000>;
			mask = <0x01>;
			linux,phandle = <0x57>;
			phandle = <0x57>;
		};

		recovery {
			pname = "recovery";
			size = <0x00 0x1800000>;
			mask = <0x01>;
			linux,phandle = <0x58>;
			phandle = <0x58>;
		};

		misc {
			pname = "misc";
			size = <0x00 0x800000>;
			mask = <0x01>;
			linux,phandle = <0x59>;
			phandle = <0x59>;
		};

		dtbo {
			pname = "dtbo";
			size = <0x00 0x800000>;
			mask = <0x01>;
			linux,phandle = <0x5a>;
			phandle = <0x5a>;
		};

		cri_data {
			pname = "cri_data";
			size = <0x00 0x800000>;
			mask = <0x02>;
			linux,phandle = <0x5b>;
			phandle = <0x5b>;
		};

		rsv {
			pname = "rsv";
			size = <0x00 0x1000000>;
			mask = <0x01>;
			linux,phandle = <0x5e>;
			phandle = <0x5e>;
		};

		metadata {
			pname = "metadata";
			size = <0x00 0x1000000>;
			mask = <0x01>;
			linux,phandle = <0x5f>;
			phandle = <0x5f>;
		};

		vbmeta {
			pname = "vbmeta";
			size = <0x00 0x200000>;
			mask = <0x01>;
			linux,phandle = <0x60>;
			phandle = <0x60>;
		};

		param {
			pname = "param";
			size = <0x00 0x1000000>;
			mask = <0x02>;
			linux,phandle = <0x5c>;
			phandle = <0x5c>;
		};

		boot {
			pname = "boot";
			size = <0x00 0x1000000>;
			mask = <0x01>;
			linux,phandle = <0x5d>;
			phandle = <0x5d>;
		};

		tee {
			pname = "tee";
			size = <0x00 0x2000000>;
			mask = <0x01>;
			linux,phandle = <0x61>;
			phandle = <0x61>;
		};

		vendor {
			pname = "vendor";
			size = <0x00 0x10000000>;
			mask = <0x01>;
			linux,phandle = <0x62>;
			phandle = <0x62>;
		};

		odm {
			pname = "odm";
			size = <0x00 0x8000000>;
			mask = <0x01>;
			linux,phandle = <0x63>;
			phandle = <0x63>;
		};

		system {
			pname = "system";
			size = <0x00 0x46000000>;
			mask = <0x01>;
			linux,phandle = <0x64>;
			phandle = <0x64>;
		};

		product {
			pname = "product";
			size = <0x00 0x8000000>;
			mask = <0x01>;
			linux,phandle = <0x65>;
			phandle = <0x65>;
		};

		cache {
			pname = "cache";
			size = <0x00 0x26000000>;
			mask = <0x02>;
			linux,phandle = <0x66>;
			phandle = <0x66>;
		};

		nes_data {
			pname = "nes_data";
			size = <0x00 0x3000000>;
			mask = <0x02>;
			linux,phandle = <0x67>;
			phandle = <0x67>;
		};

		data {
			pname = "data";
			size = <0xffffffff 0xffffffff>;
			mask = <0x04>;
			linux,phandle = <0x68>;
			phandle = <0x68>;
		};
	};

	aliases {
		serial0 = "/soc/aobus@ff800000/serial@3000";
		serial1 = "/serial@ffd24000";
		serial2 = "/serial@ffd23000";
		serial3 = "/serial@ffd22000";
		serial4 = "/soc/aobus@ff800000/serial@4000";
		tsensor0 = "/p_tsensor@ff634594";
		tsensor1 = "/d_tsensor@ff800228";
		i2c0 = "/soc/cbus@ffd00000/i2c@1f000";
		i2c1 = "/soc/cbus@ffd00000/i2c@1e000";
		i2c2 = "/soc/cbus@ffd00000/i2c@1d000";
		i2c3 = "/soc/cbus@ffd00000/i2c@1c000";
		i2c4 = "/soc/aobus@ff800000/i2c@5000";
	};

	memory@00000000 {
		device_type = "memory";
		linux,usable-memory = <0x00 0x100000 0x00 0x3ff00000>;
	};

	reserved-memory {
		#address-cells = <0x02>;
		#size-cells = <0x02>;
		ranges;

		ramoops@0x07400000 {
			compatible = "ramoops";
			reg = <0x00 0x7400000 0x00 0x100000>;
			record-size = <0x8000>;
			console-size = <0x8000>;
			ftrace-size = <0x00>;
			pmsg-size = <0x8000>;
		};

		linux,secmon {
			compatible = "shared-dma-pool";
			reusable;
			size = <0x00 0x400000>;
			alignment = <0x00 0x400000>;
			alloc-ranges = <0x00 0x5000000 0x00 0x400000>;
			linux,phandle = <0x0f>;
			phandle = <0x0f>;
		};

		linux,secos {
			status = "disable";
			compatible = "amlogic, aml_secos_memory";
			reg = <0x00 0x5300000 0x00 0x2000000>;
			no-map;
			linux,phandle = <0x102>;
			phandle = <0x102>;
		};

		linux,meson-fb {
			compatible = "shared-dma-pool";
			reusable;
			size = <0x00 0x800000>;
			alignment = <0x00 0x400000>;
			alloc-ranges = <0x00 0x3f800000 0x00 0x800000>;
			linux,phandle = <0x36>;
			phandle = <0x36>;
		};

		linux,ion-dev {
			compatible = "shared-dma-pool";
			reusable;
			size = <0x00 0x4c00000>;
			alignment = <0x00 0x400000>;
			linux,phandle = <0x1b>;
			phandle = <0x1b>;
		};

		linux,di_cma {
			compatible = "shared-dma-pool";
			reusable;
			size = <0x00 0x2800000>;
			alignment = <0x00 0x400000>;
			linux,phandle = <0x70>;
			phandle = <0x70>;
		};

		linux,ppmgr {
			compatible = "shared-dma-pool";
			size = <0x00 0x00>;
			linux,phandle = <0x6f>;
			phandle = <0x6f>;
		};

		linux,codec_mm_cma {
			compatible = "shared-dma-pool";
			reusable;
			size = <0x00 0xd000000>;
			alignment = <0x00 0x400000>;
			linux,contiguous-region;
			linux,phandle = <0x6d>;
			phandle = <0x6d>;
		};

		linux,codec_mm_reserved {
			compatible = "amlogic, codec-mm-reserved";
			size = <0x00 0x00>;
			alignment = <0x00 0x100000>;
			linux,phandle = <0x6e>;
			phandle = <0x6e>;
		};

		linux,vdin0_cma {
			compatible = "shared-dma-pool";
			reusable;
			size = <0x00 0x1000000>;
			alignment = <0x00 0x400000>;
			linux,phandle = <0x34>;
			phandle = <0x34>;
		};

		linux,vdin1_cma {
			compatible = "shared-dma-pool";
			reusable;
			size = <0x00 0x1000000>;
			alignment = <0x00 0x400000>;
			linux,phandle = <0x35>;
			phandle = <0x35>;
		};
	};

	adc_keypad {
		compatible = "amlogic, adc_keypad";
		status = "okay";
		key_name = "mute";
		key_num = <0x01>;
		io-channels = <0x69 0x00>;
		io-channel-names = "key-chan-0";
		key_chan = <0x00>;
		key_code = <0x71>;
		key_val = <0x3fc>;
		key_tolerance = <0x28>;
	};

	gpioleds {
		compatible = "gpio-leds";
		status = "disable";

		net_red {
			label = "net_red";
			gpios = <0x16 0x0f 0x01>;
			default-state = "on";
		};

		net_green {
			label = "net_green";
			gpios = <0x16 0x10 0x00>;
			default-state = "on";
		};

		remote_led {
			label = "remote_led";
			gpios = <0x15 0x0a 0x01>;
			default-state = "off";
			linux,default-trigger = "rc_feedback";
		};

		sys_led {
			label = "sys_led";
			gpios = <0x15 0x0b 0x01>;
			default-state = "on";
			retain-state-suspended;
			linux,default-trigger = "cpu0";
		};
	};

	gpio_keypad {
		compatible = "amlogic, gpio_keypad";
		status = "okay";
		scan_period = <0x14>;
		key_num = <0x01>;
		key_name = "DPAD_DOWN";
		key_code = <0x6c>;
		key-gpios = <0x15 0x03 0x00>;
		interrupts = <0x00 0x46 0x01 0x00 0x47 0x02>;
		interrupt-names = "irq_keyup\0irq_keydown";
	};

	cvbsout {
		compatible = "amlogic, cvbsout-g12a";
		dev_name = "cvbsout";
		status = "okay";
		clocks = <0x02 0x55 0x02 0x4e 0x02 0x4f 0x02 0x57>;
		clock-names = "venci_top_gate\0venci_0_gate\0venci_1_gate\0vdac_clk_gate";
		performance = <0x1bf0 0x09 0x1b56 0x343 0x1b12 0x00 0x1b05 0x09 0x1c59 0xfc48 0xffff 0x00>;
		performance_telecom = <0x1bf0 0x09 0x1b56 0x333 0x1b12 0x8080 0x1b05 0xfd 0x1c59 0xf850 0xffff 0x00>;
	};

	bt-dev {
		compatible = "amlogic, bt-dev";
		dev_name = "bt-dev";
		status = "okay";
		gpio_reset = <0x16 0x53 0x00>;
		gpio_hostwake = <0x16 0x55 0x00>;
	};

	wifi {
		compatible = "amlogic, aml_wifi";
		dev_name = "aml_wifi";
		status = "okay";
		interrupt_pin = <0x16 0x49 0x00>;
		irq_trigger_type = "GPIO_IRQ_LOW";
		power_on_pin = <0x16 0x48 0x00>;
		dhd_static_buf;
		pinctrl-names = "default";
		pinctrl-0 = <0x6a>;
		pwm_config = <0x6b>;
	};

	wifi_pwm_conf {
		linux,phandle = <0x6b>;
		phandle = <0x6b>;

		pwm_channel1_conf {
			pwms = <0x6c 0x00 0x7558 0x00>;
			duty-cycle = <0x3aac>;
			times = <0x0a>;
		};

		pwm_channel2_conf {
			pwms = <0x6c 0x02 0x754e 0x00>;
			duty-cycle = <0x3aa7>;
			times = <0x0c>;
		};
	};

	codec_mm {
		compatible = "amlogic, codec, mm";
		memory-region = <0x6d 0x6e>;
		dev_name = "codec_mm";
		status = "okay";
	};

	ppmgr {
		compatible = "amlogic, ppmgr";
		memory-region = <0x6f>;
		dev_name = "ppmgr";
		status = "okay";
	};

	deinterlace {
		compatible = "amlogic, deinterlace";
		status = "okay";
		flag_cma = <0x01>;
		memory-region = <0x70>;
		interrupts = <0x00 0x2e 0x01 0x00 0x28 0x01>;
		interrupt-names = "pre_irq\0post_irq";
		clocks = <0x02 0x9b 0x02 0x9c>;
		clock-names = "vpu_clkb_tmp_composite\0vpu_clkb_composite";
		clock-range = <0x14e 0x29b>;
		buffer-size = <0x3e2c40>;
		post-wr-support = <0x01>;
		nr10bit-support = <0x01>;
		nrds-enable = <0x01>;
		pps-enable = <0x01>;
	};

	ionvideo {
		compatible = "amlogic, ionvideo";
		dev_name = "ionvideo";
		status = "okay";
	};

	dvb {
		compatible = "amlogic, dvb";
		dev_name = "dvb";
		status = "ok";
		ts2 = "parallel";
		ts2_control = <0x00>;
		ts2_invert = <0x00>;
	};

	unifykey {
		compatible = "amlogic, unifykey";
		status = "ok";
		unifykey-num = <0x17>;
		unifykey-index-0 = <0x71>;
		unifykey-index-1 = <0x72>;
		unifykey-index-2 = <0x73>;
		unifykey-index-3 = <0x74>;
		unifykey-index-4 = <0x75>;
		unifykey-index-5 = <0x76>;
		unifykey-index-6 = <0x77>;
		unifykey-index-7 = <0x78>;
		unifykey-index-8 = <0x79>;
		unifykey-index-9 = <0x7a>;
		unifykey-index-10 = <0x7b>;
		unifykey-index-11 = <0x7c>;
		unifykey-index-12 = <0x7d>;
		unifykey-index-13 = <0x7e>;
		unifykey-index-14 = <0x7f>;
		unifykey-index-15 = <0x80>;
		unifykey-index-16 = <0x81>;
		unifykey-index-17 = <0x82>;
		unifykey-index-18 = <0x83>;
		unifykey-index-19 = <0x84>;
		unifykey-index-20 = <0x85>;
		unifykey-index-21 = <0x86>;
		unifykey-index-22 = <0x87>;

		key_0 {
			key-name = "usid";
			key-device = "normal";
			key-permit = "read\0write\0del";
			linux,phandle = <0x71>;
			phandle = <0x71>;
		};

		key_1 {
			key-name = "mac";
			key-device = "normal";
			key-permit = "read\0write\0del";
			linux,phandle = <0x72>;
			phandle = <0x72>;
		};

		key_2 {
			key-name = "hdcp";
			key-device = "secure";
			key-type = "sha1";
			key-permit = "read\0write\0del";
			linux,phandle = <0x73>;
			phandle = <0x73>;
		};

		key_3 {
			key-name = "secure_boot_set";
			key-device = "efuse";
			key-permit = "write";
			linux,phandle = <0x74>;
			phandle = <0x74>;
		};

		key_4 {
			key-name = "mac_bt";
			key-device = "normal";
			key-permit = "read\0write\0del";
			key-type = "mac";
			linux,phandle = <0x75>;
			phandle = <0x75>;
		};

		key_5 {
			key-name = "mac_wifi";
			key-device = "normal";
			key-permit = "read\0write\0del";
			key-type = "mac";
			linux,phandle = <0x76>;
			phandle = <0x76>;
		};

		key_6 {
			key-name = "hdcp2_tx";
			key-device = "normal";
			key-permit = "read\0write\0del";
			linux,phandle = <0x77>;
			phandle = <0x77>;
		};

		key_7 {
			key-name = "hdcp2_rx";
			key-device = "normal";
			key-permit = "read\0write\0del";
			linux,phandle = <0x78>;
			phandle = <0x78>;
		};

		key_8 {
			key-name = "widevinekeybox";
			key-device = "secure";
			key-permit = "read\0write\0del";
			linux,phandle = <0x79>;
			phandle = <0x79>;
		};

		key_9 {
			key-name = "deviceid";
			key-device = "normal";
			key-permit = "read\0write\0del";
			linux,phandle = <0x7a>;
			phandle = <0x7a>;
		};

		key_10 {
			key-name = "hdcp22_fw_private";
			key-device = "secure";
			key-permit = "read\0write\0del";
			linux,phandle = <0x7b>;
			phandle = <0x7b>;
		};

		key_11 {
			key-name = "PlayReadykeybox25";
			key-device = "secure";
			key-permit = "read\0write\0del";
			linux,phandle = <0x7c>;
			phandle = <0x7c>;
		};

		key_12 {
			key-name = "prpubkeybox";
			key-device = "secure";
			key-permit = "read\0write\0del";
			linux,phandle = <0x7d>;
			phandle = <0x7d>;
		};

		key_13 {
			key-name = "prprivkeybox";
			key-device = "secure";
			key-permit = "read\0write\0del";
			linux,phandle = <0x7e>;
			phandle = <0x7e>;
		};

		key_14 {
			key-name = "UUID";
			key-device = "normal";
			key-permit = "read\0write\0del";
			linux,phandle = <0x7f>;
			phandle = <0x7f>;
		};

		key_15 {
			key-name = "SERIALNO";
			key-device = "normal";
			key-permit = "read\0write\0del";
			linux,phandle = <0x80>;
			phandle = <0x80>;
		};

		key_16 {
			key-name = "OrderId";
			key-device = "normal";
			key-permit = "read\0write\0del";
			linux,phandle = <0x81>;
			phandle = <0x81>;
		};

		key_17 {
			key-name = "DID";
			key-device = "normal";
			key-permit = "read\0write\0del";
			linux,phandle = <0x82>;
			phandle = <0x82>;
		};

		key_18 {
			key-name = "OTP";
			key-device = "normal";
			key-permit = "read\0write\0del";
			linux,phandle = <0x83>;
			phandle = <0x83>;
		};

		key_19 {
			key-name = "hdcp2lc128";
			key-device = "normal";
			key-permit = "read\0write\0del";
			linux,phandle = <0x84>;
			phandle = <0x84>;
		};

		key_20 {
			key-name = "hdcp2key";
			key-device = "normal";
			key-permit = "read\0write\0del";
			linux,phandle = <0x85>;
			phandle = <0x85>;
		};

		key_21 {
			key-name = "copyright";
			key-device = "normal";
			key-permit = "read\0write\0del";
			linux,phandle = <0x86>;
			phandle = <0x86>;
		};

		key_22 {
			key-name = "attestationkeybox";
			key-device = "secure";
			key-permit = "read\0write\0del";
			linux,phandle = <0x87>;
			phandle = <0x87>;
		};
	};

	efusekey {
		keynum = <0x04>;
		key0 = <0x88>;
		key1 = <0x89>;
		key2 = <0x8a>;
		key3 = <0x8b>;
		linux,phandle = <0x56>;
		phandle = <0x56>;

		key_0 {
			keyname = "mac";
			offset = <0x00>;
			size = <0x06>;
			linux,phandle = <0x88>;
			phandle = <0x88>;
		};

		key_1 {
			keyname = "mac_bt";
			offset = <0x06>;
			size = <0x06>;
			linux,phandle = <0x89>;
			phandle = <0x89>;
		};

		key_2 {
			keyname = "mac_wifi";
			offset = <0x0c>;
			size = <0x06>;
			linux,phandle = <0x8a>;
			phandle = <0x8a>;
		};

		key_3 {
			keyname = "usid";
			offset = <0x12>;
			size = <0x10>;
			linux,phandle = <0x8b>;
			phandle = <0x8b>;
		};
	};

	amlvecm {
		compatible = "amlogic, vecm";
		dev_name = "aml_vecm";
		status = "okay";
		gamma_en = <0x00>;
		wb_en = <0x00>;
		cm_en = <0x00>;
	};

	amdolby_vision {
		compatible = "amlogic, dolby_vision_g12a";
		dev_name = "aml_amdolby_vision_driver";
		status = "okay";
		tv_mode = <0x00>;
	};

	dummy {
		#sound-dai-cells = <0x00>;
		compatible = "amlogic, aml_dummy_codec";
		status = "okay";
		linux,phandle = <0x90>;
		phandle = <0x90>;
	};

	t9015 {
		#sound-dai-cells = <0x00>;
		compatible = "amlogic, aml_codec_T9015";
		reg = <0x00 0xff632000 0x00 0x2000>;
		is_auge_used = <0x01>;
		tdmout_index = <0x01>;
		status = "okay";
		linux,phandle = <0x8d>;
		phandle = <0x8d>;
	};

	max98357a {
		#sound-dai-cells = <0x00>;
		compatible = "maxim,max98357a";
		sdmode-gpios = <0x16 0x4a 0x00>;
		status = "okay";
		linux,phandle = <0x91>;
		phandle = <0x91>;
	};

	eqdrc {
		eqdrc_module = <0x01>;
		lane_mask = <0x01>;
		channel_mask = <0x03>;
		linux,phandle = <0x8e>;
		phandle = <0x8e>;
	};

	auge_sound {
		compatible = "amlogic, g12a-sound-card";
		aml-audio-card,name = "AML-AUGESOUND";
		aml-audio-card,loopback = <0x8c>;
		aml-audio-card,aux-devs = <0x8d>;
		avout_mute-gpios = <0x15 0x02 0x00>;
		aml-audio-card,effect = <0x8e>;

		aml-audio-card,dai-link@0 {
			format = "i2s";
			mclk-fs = <0x100>;
			bitclock-master = <0x8f>;
			frame-master = <0x8f>;
			suffix-name = "alsaPORT-i2s1";

			cpu {
				sound-dai = <0x8f>;
				dai-tdm-slot-tx-mask = <0x01 0x01>;
				dai-tdm-slot-rx-mask = <0x01 0x01>;
				dai-tdm-slot-num = <0x02>;
				dai-tdm-slot-width = <0x20>;
				system-clock-frequency = <0xbb8000>;
				linux,phandle = <0x103>;
				phandle = <0x103>;
			};

			codec {
				sound-dai = <0x90 0x90 0x91>;
				linux,phandle = <0x104>;
				phandle = <0x104>;
			};
		};

		aml-audio-card,dai-link@1 {
			format = "i2s";
			mclk-fs = <0x100>;
			bitclock-master = <0x92>;
			frame-master = <0x92>;
			suffix-name = "alsaPORT-i2s";

			cpu {
				sound-dai = <0x92>;
				dai-tdm-slot-tx-mask = <0x01 0x01>;
				dai-tdm-slot-rx-mask = <0x01 0x01>;
				dai-tdm-slot-num = <0x02>;
				dai-tdm-slot-width = <0x20>;
				system-clock-frequency = <0xbb8000>;
			};

			codec {
				sound-dai = <0x90 0x90 0x8d>;
				linux,phandle = <0x105>;
				phandle = <0x105>;
			};
		};

		aml-audio-card,dai-link@2 {
			format = "i2s";
			mclk-fs = <0x100>;
			bitclock-master = <0x93>;
			frame-master = <0x93>;

			cpu {
				sound-dai = <0x93>;
				dai-tdm-slot-tx-mask = <0x01 0x01>;
				dai-tdm-slot-rx-mask = <0x01 0x01>;
				dai-tdm-slot-num = <0x02>;
				dai-tdm-slot-width = <0x20>;
				system-clock-frequency = <0xbb8000>;
			};

			codec {
				sound-dai = <0x90 0x90>;
			};
		};

		aml-audio-card,dai-link@3 {
			mclk-fs = <0x40>;
			suffix-name = "alsaPORT-pdm";

			cpu {
				sound-dai = <0x94>;
			};

			codec {
				sound-dai = <0x90>;
			};
		};

		aml-audio-card,dai-link@4 {
			mclk-fs = <0x80>;
			continuous-clock;
			suffix-name = "alsaPORT-spdifb2hdmi";

			cpu {
				sound-dai = <0x95>;
				system-clock-frequency = <0x5dc000>;
			};

			codec {
				sound-dai = <0x90>;
			};
		};

		aml-audio-card,dai-link@5 {
			mclk-fs = <0x80>;
			continuous-clock;
			suffix-name = "alsaPORT-spdif";

			cpu {
				sound-dai = <0x96>;
				system-clock-frequency = <0x5dc000>;
			};

			codec {
				sound-dai = <0x90>;
			};
		};
	};

	locker {
		compatible = "amlogic, audiolocker";
		clocks = <0x1c 0x22 0x1c 0x23 0x1c 0x1a 0x1c 0x1b 0x02 0x0d 0x02 0x0e>;
		clock-names = "lock_out\0lock_in\0out_src\0in_src\0out_calc\0in_ref";
		interrupts = <0x00 0x01 0x01>;
		interrupt-names = "irq";
		frequency = <0x2ebae40>;
		dividor = <0x31>;
		status = "okay";
		linux,phandle = <0x106>;
		phandle = <0x106>;
	};

	cpu_opp_table0 {
		compatible = "operating-points-v2";
		opp-shared;
		linux,phandle = <0x0d>;
		phandle = <0x0d>;

		opp00 {
			opp-hz = <0x00 0x5f5e100>;
			opp-microvolt = <0xb2778>;
		};

		opp01 {
			opp-hz = <0x00 0xee6b280>;
			opp-microvolt = <0xb2778>;
		};

		opp02 {
			opp-hz = <0x00 0x1dcd6500>;
			opp-microvolt = <0xb2778>;
		};

		opp03 {
			opp-hz = <0x00 0x27c19cc0>;
			opp-microvolt = <0xb2778>;
		};

		opp04 {
			opp-hz = <0x00 0x3b9aca00>;
			opp-microvolt = <0xb2778>;
		};

		opp05 {
			opp-hz = <0x00 0x47868c00>;
			opp-microvolt = <0xb9ca8>;
		};

		opp06 {
			opp-hz = <0x00 0x5353c980>;
			opp-microvolt = <0xc11d8>;
		};

		opp07 {
			opp-hz = <0x00 0x5a1f4a00>;
			opp-microvolt = <0xcae18>;
		};

		opp08 {
			opp-hz = <0x00 0x5fd82200>;
			opp-microvolt = <0xd4a58>;
		};

		opp09 {
			opp-hz = <0x00 0x6590fa00>;
			opp-microvolt = <0xe0da8>;
		};

		opp10 {
			opp-hz = <0x00 0x6b49d200>;
			opp-microvolt = <0xef808>;
		};
	};

	cpufreq-meson {
		compatible = "amlogic, cpufreq-meson";
		pinctrl-names = "default";
		pinctrl-0 = <0x97>;
		status = "okay";
	};

	__symbols__ {
		gpu = "/bifrost";
		dvfs125_cfg = "/bifrost/clk125_cfg";
		dvfs250_cfg = "/bifrost/dvfs250_cfg";
		dvfs285_cfg = "/bifrost/dvfs285_cfg";
		dvfs400_cfg = "/bifrost/dvfs400_cfg";
		dvfs500_cfg = "/bifrost/dvfs500_cfg";
		dvfs666_cfg = "/bifrost/dvfs666_cfg";
		dvfs800_cfg = "/bifrost/dvfs800_cfg";
		dvfs850_cfg = "/bifrost/dvfs850_cfg";
		cpus = "/cpus";
		cluster0 = "/cpus/cpu-map/cluster0";
		CPU0 = "/cpus/cpu@0";
		CPU1 = "/cpus/cpu@1";
		CPU2 = "/cpus/cpu@2";
		CPU3 = "/cpus/cpu@3";
		CPU_SLEEP_0 = "/cpus/idle-states/cpu-sleep-0";
		gic = "/interrupt-controller@2c001000";
		meson_suspend = "/pm";
		mailbox = "/mhu@c883c400";
		xtal = "/xtal-clk";
		ethmac = "/ethernet@ff3f0000";
		pinctrl_aobus = "/pinctrl@ff800014";
		gpio_ao = "/pinctrl@ff800014/ao-bank@ff800014";
		sd_to_ao_uart_clr_pins = "/pinctrl@ff800014/sd_to_ao_uart_clr_pins";
		sd_to_ao_uart_pins = "/pinctrl@ff800014/sd_to_ao_uart_pins";
		ao_uart_pins = "/pinctrl@ff800014/ao_uart";
		ao_b_uart_pins = "/pinctrl@ff800014/ao_b_uart";
		ao_i2c_master_pins1 = "/pinctrl@ff800014/ao_i2c_pins1";
		ao_i2c_master_pins2 = "/pinctrl@ff800014/ao_i2c_pins2";
		ao_i2c_slave_pins = "/pinctrl@ff800014/ao_i2c_slave_pins";
		pwm_ao_a_pins = "/pinctrl@ff800014/pwm_ao_a";
		pwm_ao_a_hiz_pins = "/pinctrl@ff800014/pwm_ao_a_hiz";
		pwm_ao_b_pins = "/pinctrl@ff800014/pwm_ao_b";
		pwm_ao_c_pins1 = "/pinctrl@ff800014/pwm_ao_c_pins1";
		pwm_ao_c_pins2 = "/pinctrl@ff800014/pwm_ao_c_pins2";
		pwm_ao_c_hiz_pins = "/pinctrl@ff800014/pwm_ao_c_hiz";
		pwm_ao_d_pins1 = "/pinctrl@ff800014/pwm_ao_d_pins1";
		pwm_ao_d_pins2 = "/pinctrl@ff800014/pwm_ao_d_pins2";
		pwm_ao_d_pins3 = "/pinctrl@ff800014/pwm_ao_d_pins3";
		aocec_a = "/pinctrl@ff800014/ao_ceca";
		aocec_b = "/pinctrl@ff800014/ao_cecb";
		remote_pins = "/pinctrl@ff800014/remote_pin";
		irblaster_pins = "/pinctrl@ff800014/irblaster_pin";
		pinctrl_periphs = "/pinctrl@ff634480";
		gpio = "/pinctrl@ff634480/banks@ff6346c0";
		emmc_clk_cmd_pins = "/pinctrl@ff634480/emmc_clk_cmd_pins";
		emmc_conf_pull_up = "/pinctrl@ff634480/emmc_conf_pull_up";
		emmc_conf_pull_done = "/pinctrl@ff634480/emmc_conf_pull_done";
		sd_clk_cmd_pins = "/pinctrl@ff634480/sd_clk_cmd_pins";
		sd_all_pins = "/pinctrl@ff634480/sd_all_pins";
		sd_1bit_pins = "/pinctrl@ff634480/sd_1bit_pins";
		sd_clr_all_pins = "/pinctrl@ff634480/sd_clr_all_pins";
		sd_clr_noall_pins = "/pinctrl@ff634480/sd_clr_noall_pins";
		ao_to_sd_uart_pins = "/pinctrl@ff634480/ao_to_sd_uart_pins";
		sdio_clk_cmd_pins = "/pinctrl@ff634480/sdio_clk_cmd_pins";
		sdio_all_pins = "/pinctrl@ff634480/sdio_all_pins";
		sdio_x_clk_cmd_pins = "/pinctrl@ff634480/sdio_x_clk_cmd_pins";
		sdio_x_all_pins = "/pinctrl@ff634480/sdio_x_all_pins";
		sdio_x_en_pins = "/pinctrl@ff634480/sdio_x_en_pins";
		sdio_x_clr_pins = "/pinctrl@ff634480/sdio_x_clr_pins";
		all_nand_pins = "/pinctrl@ff634480/all_nand_pins";
		nand_cs_pins = "/pinctrl@ff634480/nand_cs";
		i2c0_master_pins1 = "/pinctrl@ff634480/i2c0_pins1";
		i2c0_master_pins2 = "/pinctrl@ff634480/i2c0_pins2";
		i2c0_master_pins3 = "/pinctrl@ff634480/i2c0_pins3";
		i2c1_master_pins1 = "/pinctrl@ff634480/i2c1_pins1";
		i2c1_master_pins2 = "/pinctrl@ff634480/i2c1_pins2";
		i2c1_master_pins3 = "/pinctrl@ff634480/i2c1_pins3";
		i2c2_master_pins1 = "/pinctrl@ff634480/i2c2_pins1";
		i2c2_master_pins2 = "/pinctrl@ff634480/i2c2_pins2";
		i2c3_master_pins1 = "/pinctrl@ff634480/i2c3_pins1";
		i2c3_master_pins2 = "/pinctrl@ff634480/i2c3_pins2";
		pwm_a_pins = "/pinctrl@ff634480/pwm_a";
		pwm_b_pins1 = "/pinctrl@ff634480/pwm_b_pins1";
		pwm_b_pins2 = "/pinctrl@ff634480/pwm_b_pins2";
		pwm_c_pins1 = "/pinctrl@ff634480/pwm_c_pins1";
		pwm_c_pins2 = "/pinctrl@ff634480/pwm_c_pins2";
		pwm_c_pins3 = "/pinctrl@ff634480/pwm_c_pins3";
		pwm_d_pins1 = "/pinctrl@ff634480/pwm_d_pins1";
		pwm_d_pins2 = "/pinctrl@ff634480/pwm_d_pins2";
		pwm_e_pins = "/pinctrl@ff634480/pwm_e";
		pwm_f_pins1 = "/pinctrl@ff634480/pwm_f_pins1";
		pwm_f_pins2 = "/pinctrl@ff634480/pwm_f_pins2";
		spicc0_pins_x = "/pinctrl@ff634480/spicc0_pins_x";
		spicc0_pins_c = "/pinctrl@ff634480/spicc0_pins_c";
		spicc1_pins = "/pinctrl@ff634480/spicc1_pins";
		a_uart_pins = "/pinctrl@ff634480/a_uart";
		b_uart_pins = "/pinctrl@ff634480/b_uart";
		c_uart_pins = "/pinctrl@ff634480/c_uart";
		hdmitx_hpd = "/pinctrl@ff634480/hdmitx_hpd";
		hdmitx_hpd_gpio = "/pinctrl@ff634480/hdmitx_hpd_gpio";
		hdmitx_ddc = "/pinctrl@ff634480/hdmitx_ddc";
		eecec_a = "/pinctrl@ff634480/ee_ceca";
		eecec_b = "/pinctrl@ff634480/ee_cecb";
		internal_eth_pins = "/pinctrl@ff634480/internal_eth_pins";
		internal_gpio_pins = "/pinctrl@ff634480/internal_gpio_pins";
		external_eth_pins = "/pinctrl@ff634480/external_eth_pins";
		tdmout_a = "/pinctrl@ff634480/tdmout_a";
		tdmb_mclk = "/pinctrl@ff634480/tdmb_mclk";
		tdmout_b = "/pinctrl@ff634480/tdmout_b";
		tdmin_b = "/pinctrl@ff634480/tdmin_b";
		tdmc_mclk = "/pinctrl@ff634480/tdmc_mclk";
		tdmin_c = "/pinctrl@ff634480/tdmin_c";
		spdifin = "/pinctrl@ff634480/spdifin";
		spdifout = "/pinctrl@ff634480/spdifout";
		pdmin = "/pinctrl@ff634480/pdmin";
		audio_data = "/audio_data";
		dwc3 = "/dwc3@ff500000";
		usb2_phy_v2 = "/usb2phy@ffe09000";
		usb3_phy_v2 = "/usb3phy@ffe09080";
		dwc2_a = "/dwc2_a@ff400000";
		wdt = "/watchdog@0xffd0f0d0";
		saradc = "/saradc";
		p_tsensor = "/p_tsensor@ff634594";
		d_tsensor = "/d_tsensor@ff800228";
		cbus = "/soc/cbus@ffd00000";
		gpio_intc = "/soc/cbus@ffd00000/interrupt-controller@f080";
		pwm_ab = "/soc/cbus@ffd00000/pwm@1b000";
		pwm_cd = "/soc/cbus@ffd00000/pwm@1a000";
		pwm_ef = "/soc/cbus@ffd00000/pwm@19000";
		i2c0 = "/soc/cbus@ffd00000/i2c@1f000";
		i2c1 = "/soc/cbus@ffd00000/i2c@1e000";
		i2c2 = "/soc/cbus@ffd00000/i2c@1d000";
		i2c3 = "/soc/cbus@ffd00000/i2c@1c000";
		ad82584f_62 = "/soc/cbus@ffd00000/i2c@1c000/ad82584f_62@62";
		tas5707_36 = "/soc/cbus@ffd00000/i2c@1c000/tas5707_36@36";
		spicc0 = "/soc/cbus@ffd00000/spi@13000";
		spicc1 = "/soc/cbus@ffd00000/spi@15000";
		aobus = "/soc/aobus@ff800000";
		aoclkc = "/soc/aobus@ff800000/clock-controller@0";
		pwm_AO_ab = "/soc/aobus@ff800000/pwm@7000";
		pwm_AO_cd = "/soc/aobus@ff800000/pwm@2000";
		i2c_AO = "/soc/aobus@ff800000/i2c@5000";
		i2c_AO_slave = "/soc/aobus@ff800000/i2c_slave@6000";
		uart_AO = "/soc/aobus@ff800000/serial@3000";
		uart_AO_B = "/soc/aobus@ff800000/serial@4000";
		periphs = "/soc/periphs@ff634400";
		hiubus = "/soc/hiubus@ff63c000";
		clkc = "/soc/hiubus@ff63c000/clock-controller@0";
		audiobus = "/soc/audiobus@0xff642000";
		clkaudio = "/soc/audiobus@0xff642000/audio_clocks";
		aml_tdma = "/soc/audiobus@0xff642000/tdma";
		aml_tdmb = "/soc/audiobus@0xff642000/tdmb";
		aml_tdmc = "/soc/audiobus@0xff642000/tdmc";
		aml_i2s2hdmi = "/soc/audiobus@0xff642000/i2s2hdmi";
		aml_spdif = "/soc/audiobus@0xff642000/spdif";
		aml_spdif_b = "/soc/audiobus@0xff642000/spdif_b";
		aml_pdm = "/soc/audiobus@0xff642000/pdm";
		aml_loopback = "/soc/audiobus@0xff642000/loopback";
		audioresample = "/soc/audiobus@0xff642000/resample";
		aml_pwrdet = "/soc/audiobus@0xff642000/pwrdet";
		remote = "/rc@0xff808040";
		custom_maps = "/custom_maps";
		map_0 = "/custom_maps/map_0";
		map_1 = "/custom_maps/map_1";
		map_2 = "/custom_maps/map_2";
		uart_A = "/serial@ffd24000";
		uart_B = "/serial@ffd23000";
		uart_C = "/serial@ffd22000";
		pcie_A = "/pcieA@fc000000";
		amhdmitx = "/amhdmitx";
		vend_data = "/amhdmitx/vend_data";
		aocec = "/aocec";
		vdin0 = "/vdin0";
		vdin1 = "/vdin1";
		canvas = "/canvas";
		codec_io = "/codec_io";
		meson_fb = "/meson-fb";
		irblaster = "/meson-irblaster";
		sd_emmc_c = "/emmc@ffe07000";
		sd_emmc_b1 = "/sd1@ffe05000";
		sd_emmc_b2 = "/sd2@ffe05000";
		sd_emmc_a = "/sdio@ffe03000";
		nand = "/nfc@0";
		bootloader = "/nfc@0/bootloader";
		nandnormal = "/nfc@0/nandnormal";
		nand_partitions = "/nfc@0/nand_partition";
		meson_cooldev = "/meson-cooldev@0";
		cpufreq_cool0 = "/meson-cooldev@0/cpufreq_cool0";
		cpucore_cool0 = "/meson-cooldev@0/cpucore_cool0";
		gpufreq_cool0 = "/meson-cooldev@0/gpufreq_cool0";
		gpucore_cool0 = "/meson-cooldev@0/gpucore_cool0";
		soc_thermal = "/thermal-zones/soc_thermal";
		pswitch_on = "/thermal-zones/soc_thermal/trips/trip-point@0";
		pcontrol = "/thermal-zones/soc_thermal/trips/trip-point@1";
		phot = "/thermal-zones/soc_thermal/trips/trip-point@2";
		pcritical = "/thermal-zones/soc_thermal/trips/trip-point@3";
		ddr_thermal = "/thermal-zones/ddr_thermal";
		dswitch_on = "/thermal-zones/ddr_thermal/trips/trip-point@0";
		dcontrol = "/thermal-zones/ddr_thermal/trips/trip-point@1";
		dhot = "/thermal-zones/ddr_thermal/trips/trip-point@2";
		dcritical = "/thermal-zones/ddr_thermal/trips/trip-point@3";
		vddcpu0 = "/pwmao_d-regulator";
		defendkey = "/defendkey";
		efuse = "/efuse";
		partitions = "/partitions";
		logo = "/partitions/logo";
		recovery = "/partitions/recovery";
		misc = "/partitions/misc";
		dtbo = "/partitions/dtbo";
		cri_data = "/partitions/cri_data";
		rsv = "/partitions/rsv";
		metadata = "/partitions/metadata";
		vbmeta = "/partitions/vbmeta";
		param = "/partitions/param";
		boot = "/partitions/boot";
		tee = "/partitions/tee";
		vendor = "/partitions/vendor";
		odm = "/partitions/odm";
		system = "/partitions/system";
		product = "/partitions/product";
		cache = "/partitions/cache";
		nes_data = "/partitions/nes_data";
		data = "/partitions/data";
		secmon_reserved = "/reserved-memory/linux,secmon";
		secos_reserved = "/reserved-memory/linux,secos";
		logo_reserved = "/reserved-memory/linux,meson-fb";
		ion_cma_reserved = "/reserved-memory/linux,ion-dev";
		di_cma_reserved = "/reserved-memory/linux,di_cma";
		ppmgr_reserved = "/reserved-memory/linux,ppmgr";
		codec_mm_cma = "/reserved-memory/linux,codec_mm_cma";
		codec_mm_reserved = "/reserved-memory/linux,codec_mm_reserved";
		vdin0_cma_reserved = "/reserved-memory/linux,vdin0_cma";
		vdin1_cma_reserved = "/reserved-memory/linux,vdin1_cma";
		wifi_pwm_conf = "/wifi_pwm_conf";
		keysn_0 = "/unifykey/key_0";
		keysn_1 = "/unifykey/key_1";
		keysn_2 = "/unifykey/key_2";
		keysn_3 = "/unifykey/key_3";
		keysn_4 = "/unifykey/key_4";
		keysn_5 = "/unifykey/key_5";
		keysn_6 = "/unifykey/key_6";
		keysn_7 = "/unifykey/key_7";
		keysn_8 = "/unifykey/key_8";
		keysn_9 = "/unifykey/key_9";
		keysn_10 = "/unifykey/key_10";
		keysn_11 = "/unifykey/key_11";
		keysn_12 = "/unifykey/key_12";
		keysn_13 = "/unifykey/key_13";
		keysn_14 = "/unifykey/key_14";
		keysn_15 = "/unifykey/key_15";
		keysn_16 = "/unifykey/key_16";
		keysn_17 = "/unifykey/key_17";
		keysn_18 = "/unifykey/key_18";
		keysn_19 = "/unifykey/key_19";
		keysn_20 = "/unifykey/key_20";
		keysn_21 = "/unifykey/key_21";
		keysn_22 = "/unifykey/key_22";
		efusekey = "/efusekey";
		key_0 = "/efusekey/key_0";
		key_1 = "/efusekey/key_1";
		key_2 = "/efusekey/key_2";
		key_3 = "/efusekey/key_3";
		dummy_codec = "/dummy";
		pdm_codec = "/dummy";
		amlogic_codec = "/t9015";
		max98357a = "/max98357a";
		audio_effect = "/eqdrc";
		tdmacpu = "/auge_sound/aml-audio-card,dai-link@0/cpu";
		tdmacodec = "/auge_sound/aml-audio-card,dai-link@0/codec";
		tdmbcodec = "/auge_sound/aml-audio-card,dai-link@1/codec";
		audiolocker = "/locker";
		cpu_opp_table0 = "/cpu_opp_table0";
	};
};
